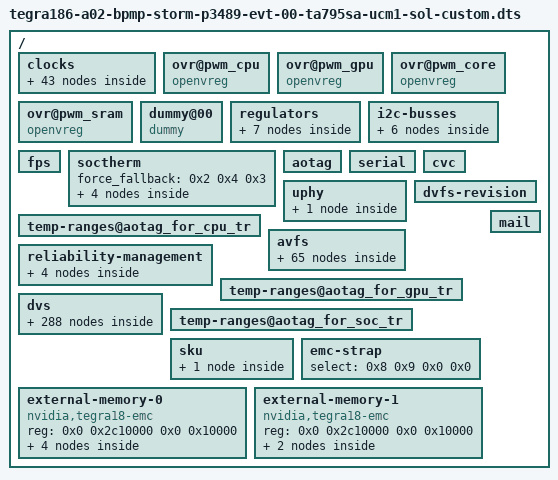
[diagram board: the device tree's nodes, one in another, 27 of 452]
/dts-v1/;

/ {
	#address-cells = <0x2>;
	#size-cells = <0x2>;

	clocks {

		init {
			i2c1 = <0x2f 0x10d 0x0 0x0>;
			i2c2 = <0xda 0x10d 0x0 0x0>;
			i2c3 = <0x4b 0x10d 0x0 0x0>;
			i2c4 = <0x56 0x10d 0x0 0x0>;
			i2c6 = <0x7d 0x10d 0x0 0x0>;
			i2c7 = <0xb6 0x10d 0x0 0x0>;
			i2c8 = <0xdb 0x10d 0x0 0x0>;
			i2c9 = <0xb7 0x10d 0x0 0x0>;
			i2c_slow = <0x5c 0x260 0x0 0x0>;
			aon_i2c_slow = <0xdd 0x260 0x0 0x0>;
			vi_i2c = <0x85 0x10d 0x0 0x0>;
			i2c12 = <0xb8 0x10d 0x0 0x0>;
			i2c13 = <0xb9 0x10d 0x0 0x0>;
			i2c14 = <0xba 0x10d 0x0 0x0>;
			xusb = <0x6f 0x10d 0x6146580 0x0>;
			xusb_core_dev = <0xf3 0x10d 0x6146580 0x0>;
			xusb_falcon = <0xf4 0x10d 0xc28cb00 0x0>;
			xusb_fs = <0xf5 0x112 0x2dc6c00 0x0>;
			xusb_core_ss = <0xf2 0x113 0x7270e00 0x0>;
			pllc4_vco = <0x20c 0x0 0x2faf0800 0x0>;
			pllc4_out0 = <0x114 0x0 0xbebc200 0x0>;
			hsic_trk = <0xf1 0x0 0x927c00 0x0>;
			pll_a1 = <0x20d 0x0 0x38be5e00 0x0>;
			aclk = <0x111 0x20d 0x11e1a300 0x0>;
			isp = <0x32 0x236 0x338eda40 0x0>;
			nvdec = <0x81 0x237 0x362e3d40 0x0>;
			nvenc = <0x83 0x238 0x350c5280 0x0>;
			nvjpg = <0x82 0x239 0x26906fc0 0x0>;
			se0 = <0x67 0x0 0x0 0x1>;
			se1 = <0x67 0x23b 0x2bde7800 0x0>;
			tsec0 = <0x51 0x0 0x0 0x20000>;
			tsec1 = <0x51 0x23c 0x1c9c3800 0x0>;
			tsecb = <0x89 0x23d 0x22274940 0x0>;
			vi = <0x33 0x23e 0x2eaba1c0 0x0>;
			vic = <0x7f 0x23f 0x2ee8aac0 0x0>;
			pll_disphub = <0x20f 0x0 0x1e53ac00 0x0>;
			nvdisplayhub = <0x9e 0x20f 0x0 0x0>;
			nafll_bpmp = <0x235 0x0 0x124f8000 0x0>;
			bpmp_apb = <0xc7 0x10d 0x0 0x0>;
			bpmp_cpu_nic = <0xc5 0x235 0x0 0x0>;
			hda = <0x66 0x10d 0x30a32c0 0x0>;
			hda2codec_2x = <0x58 0x10d 0x2dc6c00 0x0>;
			extperiph1 = <0x59 0x10d 0x0 0x0>;
			extperiph2 = <0x5a 0x10d 0x0 0x0>;
			sce_cpu_nic = <0xe4 0x23a 0x2bfcfc80 0x0>;
			sce_apb = <0xe6 0x10d 0x6146580 0x0>;
			aon_cpu = <0xd0 0x264 0x249f000 0x1>;
			aon_apb = <0xd6 0x264 0x249f000 0x1>;
			uart_fst_mipical = <0x7e 0x10d 0x40d9900 0x0>;
			aud_mclk = <0x7c 0x0 0x1770000 0x0>;
			pllnvcsi = <0x20e 0x0 0x1ad27480 0x0>;
			pll_a = <0x10f 0x0 0xf60c480 0x0>;
			axi_cbb = <0x95 0x234 0x6146580 0x0>;
			plla_out1 = <0x120 0x0 0x8f0d180 0x0>;
			ape = <0x69 0x120 0x0 0x20000>;
			host1x = <0x39 0x209 0x1d9f9e40 0x0>;
			tsec = <0x51 0x23c 0x22274940 0x0>;
			pllc2 = <0x209 0x0 0x1d9f9e40 0x0>;
			adsp = <0x111 0x20d 0x38be5e00 0x0>;
		};

		clock@bpmp_apb {
			clk-id = <0xc7>;
			allowed-parents = <0x10d 0x260 0x261>;
			mrq_hide = <0x1>;
		};

		clock@sce_apb {
			clk-id = <0xe6>;
			allowed-parents = <0x10d 0x260 0x261>;
		};

		clock@bpmp_nic {
			clk-id = <0x11f>;
			mrq_hide = <0x1>;
		};

		clock@axi_cbb {
			clk-id = <0x95>;
			allowed-parents = <0x234>;
		};

		clock@bpmp_cpu_nic {
			clk-id = <0xc5>;
			allowed-parents = <0x235>;
			mrq_hide = <0x1>;
		};

		clock@isp {
			clk-id = <0x32>;
			allowed-parents = <0x236>;
		};

		clock@nvdec {
			clk-id = <0x81>;
			allowed-parents = <0x237>;
		};

		clock@nvenc {
			clk-id = <0x83>;
			allowed-parents = <0x238>;
		};

		clock@nvjpg {
			clk-id = <0x82>;
			allowed-parents = <0x239>;
		};

		clock@sce_cpu_nic {
			clk-id = <0xe4>;
			allowed-parents = <0x23a>;
		};

		clock@se {
			clk-id = <0x67>;
			allowed-parents = <0x23b>;
		};

		clock@tsec {
			clk-id = <0x51>;
			allowed-parents = <0x23c>;
		};

		clock@tsecb {
			clk-id = <0x89>;
			allowed-parents = <0x23d>;
		};

		clock@vi {
			clk-id = <0x33>;
			allowed-parents = <0x23e>;
		};

		clock@vic {
			clk-id = <0x7f>;
			allowed-parents = <0x23f>;
		};

		clock@i2c_slow {
			clk-id = <0x5c>;
			allowed-parents = <0x260>;
		};

		clock@aon_i2c_slow {
			clk-id = <0xdd>;
			allowed-parents = <0x260>;
		};

		clock@nafll_axi_cbb {
			clk-id = <0x234>;
			mrq_hide = <0x1>;
		};

		clock@nafll_bpmp {
			clk-id = <0x235>;
			mrq_hide = <0x1>;
		};

		clock@nafll_isp {
			clk-id = <0x236>;
			mrq_hide = <0x1>;
		};

		clock@nafll_nvdec {
			clk-id = <0x237>;
			mrq_hide = <0x1>;
		};

		clock@nafll_nvenc {
			clk-id = <0x238>;
			mrq_hide = <0x1>;
		};

		clock@nafll_nvjpg {
			clk-id = <0x239>;
			mrq_hide = <0x1>;
		};

		clock@nafll_sce {
			clk-id = <0x23a>;
			mrq_hide = <0x1>;
		};

		clock@nafll_se {
			clk-id = <0x23b>;
			mrq_hide = <0x1>;
		};

		clock@nafll_tsec {
			clk-id = <0x23c>;
			mrq_hide = <0x1>;
		};

		clock@nafll_tsecb {
			clk-id = <0x23d>;
			mrq_hide = <0x1>;
		};

		clock@nafll_vi {
			clk-id = <0x23e>;
			mrq_hide = <0x1>;
		};

		clock@nafll_vic {
			clk-id = <0x23f>;
			mrq_hide = <0x1>;
		};

		clock@nafll_gpu {
			clk-id = <0x241>;
			mrq_hide = <0x1>;
		};

		clock@nafll_bcpu {
			clk-id = <0x243>;
			mrq_hide = <0x1>;
		};

		clock@nafll_mcpu {
			clk-id = <0x242>;
			mrq_hide = <0x1>;
		};

		clock@hda2codec_2x {
			clk-id = <0x58>;
			allow_fractional_divider = <0x1>;
		};

		clock@spdif_in {
			clk-id = <0x2c>;
			allow_fractional_divider = <0x1>;
		};

		clock@uarta {
			clk-id = <0x37>;
			allow_fractional_divider = <0x1>;
		};

		clock@uartb {
			clk-id = <0x38>;
			allow_fractional_divider = <0x1>;
		};

		clock@uartc {
			clk-id = <0xd7>;
			allow_fractional_divider = <0x1>;
		};

		clock@uartd {
			clk-id = <0x4d>;
			allow_fractional_divider = <0x1>;
		};

		clock@uarte {
			clk-id = <0xc2>;
			allow_fractional_divider = <0x1>;
		};

		clock@uartf {
			clk-id = <0xc3>;
			allow_fractional_divider = <0x1>;
		};

		clock@uartg {
			clk-id = <0xd8>;
			allow_fractional_divider = <0x1>;
		};

		clock@sdmmc2 {
			clk-id = <0x35>;
			allow_fractional_divider = <0x1>;
		};
	};

	ovr@pwm_cpu {
		compatible = "openvreg";
		pwm-rate = <0x5dc00>;
		pwm-off-uv = <0x927c0>;
		pwm-id = <0x7>;
		pwm-on-uv = <0x118c30>;
		enable-gpio = <0x3c>;
		linux,phandle = <0x1>;
		phandle = <0x1>;
	};

	ovr@pwm_gpu {
		compatible = "openvreg";
		pwm-rate = <0x5dc00>;
		pwm-off-uv = <0x927c0>;
		enable-gpio = <0xffff>;
		pwm-id = <0x8>;
		pwm-on-uv = <0x124f80>;
		linux,phandle = <0x3>;
		phandle = <0x3>;
	};

	ovr@pwm_core {
		compatible = "openvreg";
		pwm-rate = <0x5dc00>;
		pwm-off-uv = <0x927c0>;
		pwm-id = <0x6>;
		pwm-on-uv = <0x118c30>;
		linux,phandle = <0x5>;
		phandle = <0x5>;
	};

	ovr@pwm_sram {
		compatible = "openvreg";
		pwm-rate = <0x5dc00>;
		pwm-off-uv = <0x927c0>;
	};

	dummy@00 {
		compatible = "dummy";
		linux,phandle = <0x7>;
		phandle = <0x7>;
	};

	regulators {

		vdd_cpu {
			rail-id = <0x0 0x1>;
			dev = <0x1>;
			regulator-ramp-delay = <0xfc>;
			regulator-enable-ramp-delay = <0xa28>;
			regulator-disable-ramp-delay = <0x2ee0>;
			regulator-init-microvolt = <0xe7ef0>;
			temp-ranges = <0x2>;
			regulator-min-microvolt = <0xbbfd0 0xa6040 0xa6040 0xa6040 0xbbfd0>;
			regulator-max-microvolt = <0xef420>;
		};

		vdd_gpu {
			rail-id = <0x3>;
			dev = <0x3>;
			regulator-ramp-delay = <0xd0>;
			regulator-enable-ramp-delay = <0x7d0>;
			regulator-disable-ramp-delay = <0x2ee0>;
			regulator-init-microvolt = <0xe7ef0>;
			temp-ranges = <0x4>;
			regulator-min-microvolt = <0xbbfd0 0xa6040 0xa6040 0xa6040 0xbbfd0>;
			regulator-max-microvolt = <0xef420>;
		};

		vdd_core {
			rail-id = <0x2>;
			dev = <0x5>;
			regulator-ramp-delay = <0xd78>;
			regulator-enable-ramp-delay = <0x208>;
			regulator-disable-ramp-delay = <0x7d0>;
			regulator-init-microvolt = <0xe7ef0>;
			temp-ranges = <0x6>;
			regulator-min-microvolt = <0xaae60>;
			regulator-max-microvolt = <0x124f80>;

			bin@1717 {
				bin-bottom = <0x6b5>;
				regulator-min-microvolt = <0xe7ef0 0xb98c0 0xb98c0 0xb98c0 0xe7ef0>;
				regulator-max-microvolt = <0xef420>;
			};

			bin@1575 {
				bin-bottom = <0x627>;
				regulator-min-microvolt = <0xe7ef0 0xc3500 0xc3500 0xc3500 0xe7ef0>;
				regulator-max-microvolt = <0xef420>;
			};

			bin@1454 {
				bin-bottom = <0x5ae>;
				regulator-min-microvolt = <0xe7ef0 0xcaa30 0xcaa30 0xcaa30 0xe7ef0>;
				regulator-max-microvolt = <0xef420>;
			};
		};

		vdd_aon {
			rail-id = <0x6>;
			dev = <0x7>;
			regulator-min-microvolt = <0xc8320>;
			regulator-max-microvolt = <0xf9060>;
		};
	};

	i2c-busses {

		i2c5 {
			i2c-id = <0x5>;
			controller-clock = <0x81b3200>;
			bus-clock = <0xf4240>;
			tlow-plus-thigh = <0x8>;
			thigh = <0x2>;
			tlow = <0x4>;

			i2c_firewall_rules {

				i2c_firewall_rule@0 {
					action = <0x2>;
					addr_range_type = <0x1>;
					addr_range_low = <0x38>;
					addr_range_high = <0x3b>;
				};
			};
		};

		i2c10 {
			i2c-id = <0xa>;
			controller-clock = <0x81b3200>;
			bus-clock = <0xf4240>;
			tlow-plus-thigh = <0x8>;
			thigh = <0x2>;
			tlow = <0x4>;

			i2c_firewall_rules {

				i2c_firewall_rule@0 {
					action = <0x2>;
					addr_range_type = <0x1>;
					addr_range_low = <0x0>;
					addr_range_high = <0xff>;
				};
			};
		};
	};

	fps {
		reboot-sequence = [3c 2f 00 fc 00 3e];
		shutdown-sequence = [fc 00 3c ff 07 d0 3c 40 1a 3c 38 01 ff 0b d0 fd 00 68 3c 2f 00 3c 42 07 3c 41 c0 fc 00 3e];
		hibernate-late-sequence = [ff 17 70 3c 40 1a 3c 38 01 ff 0b d0 3c 2f 00 fc 00 3e ff 01 3c];
		resume-early-sequence = [3c 2f ce fd 00 3e ff 01 3c 3c 38 09 ff 07 d0 3c 40 1e ff 07 d0];
		sc7-sequence = [3c 1d 70 3c 1e 70 3c 1f 70 3c 20 70 3c 21 70];
		sc7-exit-sequence = [3c 1d 74 3c 1e 74 3c 1f 74 3c 20 74 3c 21 44];
	};

	soctherm {
		force_fallback = <0x2 0x4 0x3>;

		thermtrip {
			thermtrip = <0x5 0x18a88>;
		};

		throttle {
			throttle_1 = <0x2 0x184ac 0x2 0x0>;
			throttle_2 = <0x4 0x184ac 0x2 0x0>;
		};

		throttlectl {
			throttlectl_heavy = <0x1 0x7 0x7 0x64>;
		};

		edp_oc {
			oc_5 = <0x4 0x1 0x2 0x2 0x3 0x0 0xffffffff>;
		};
	};

	aotag {
		thermtrip = <0x18a88>;
		hsm_trip = <0x184ac>;
	};

	serial {
		port = <0x7>;
		has_input;
	};

	cvc {
		threshold = <0x3e8>;
		limit = <0x5>;
		jiggle;
	};

	uphy {
		lane0-owner = <0x1>;
		lane1-owner = <0x2>;
		lane2-owner = <0x1>;
		lane4-owner = <0x1>;
		lane5-owner = <0x3>;

		sata-fuse-override {
			tx-drv-amp-sel1 = <0x20>;
		};
	};

	dvfs-revision {
		mcpu = <0x2>;
		bcpu = <0x2>;
		gpu = <0x2>;
		soc-big-blocks = <0x1>;
		soc-io = <0x56>;
	};

	temp-ranges@aotag_for_cpu_tr {
		thermzone-id = <0x6>;
		tranges = <0xffffffd8 0x1e 0x19 0x32 0x2d 0x4b 0x46 0x69 0xffffffd8 0x69>;
		linux,phandle = <0x2>;
		phandle = <0x2>;
	};

	avfs {

		clock@mcpu_avfs {
			clk-id = <0x242>;
			temp-ranges = <0x2>;
			pdiv = <0x1>;
			mdiv = <0x1>;
			vfgain = <0xe 0xe 0xe 0xe 0xe 0x989680>;
			coeffs = <0xc5f71cae 0x4119cbb7 0x4640f93d 0x4025ced4 0xbb0cd89d 0xc0e99c3e 0xbfb78034 0xbb1cabb7 0xc56e31e6 0xb89a2c22>;
			vmin = <0x3f451eb8 0x0 0x0 0x3f6b5a86 0xb9187684 0x0 0x3f6b5a86 0xb9187684 0x0 0x3f6b5a86 0xb9187684 0x0 0x3f451eb8 0x0 0x0>;
			max-frequency = <0x0 0x74bad000>;
			edvd-params = <0x148060f>;
			edvd-config = <0x168>;
		};

		clock@bcpu_avfs {
			clk-id = <0x243>;
			temp-ranges = <0x2>;
			pdiv = <0x1>;
			mdiv = <0x1>;
			vfgain = <0xe 0xe 0xe 0xe 0xe 0x989680>;
			coeffs = <0xc5de9afa 0x412ca0de 0x464ad8da 0x3fa49e6e 0xbb2b6495 0xc0f8962a 0xbfde3d78 0xbb26730f 0xc56c1d32 0x39b9257a>;
			vmin = <0x3f451eb8 0x0 0x0 0x3f656d5d 0xb9212a88 0x0 0x3f656d5d 0xb9212a88 0x0 0x3f656d5d 0xb9212a88 0x0 0x3f451eb8 0x0 0x0>;
			max-frequency = <0x0 0x7270e000>;
			edvd-params = <0x148060f>;
			edvd-config = <0x168>;
		};

		clock@gpu_avfs {
			clk-id = <0x241>;
			temp-ranges = <0x4>;
			pdiv = <0x1>;
			mdiv = <0x8>;
			use-auto-skipper = <0x1>;
			vfgain = <0x2 0x2 0x2 0x2 0x2 0x989680>;
			coeffs = <0xc5f6651e 0x4157f21b 0x467f4698 0x3ee4f20b 0xbb380ca0 0xc129f43f 0xbfbf32a8 0xbb7821f9 0xc5ab0bed 0x3a204c62>;
			vmin = <0x3f451eb8 0x0 0x0 0x3f59999a 0xb8f161d8 0x0 0x3f59999a 0xb8f161d8 0x0 0x3f59999a 0xb8f161d8 0x0 0x3f451eb8 0x0 0x0>;
			max-frequency = <0x0 0x936e9d60>;

			clvc {
				use-freq-clvc = <0x1>;
				max-uvreq-offset = <0x9c40>;
				kp = <0x39d1b717>;
				min-error-threshold = <0x1820c20>;
				max-adj-step-uv = <0x2710>;
			};
		};

		clock@bpmp_avfs {
			clk-id = <0x235>;
			temp-ranges = <0x6>;
			pdiv = <0x1>;
			mdiv = <0x3>;
			use-auto-skipper = <0x1>;
			vfgain = <0x6 0x6 0x6 0x6 0x6 0x989680>;
			max-frequency = <0x0 0x314b04c0>;

			clvc {
				use-freq-clvc = <0x1>;
				max-uvreq-offset = <0x9c40>;
				kp = <0x39d1b717>;
				min-error-threshold = <0xc042c0>;
				max-adj-step-uv = <0x2710>;
				floor-uvreq = <0x1>;
			};

			bin@1717 {
				bin-bottom = <0x6b5>;
				coeffs = <0xc50e5aee 0x0 0x45b1d6b9 0x0 0x0 0x0 0x0 0x0 0xc519c49f 0x0>;
				vmin = <0x3f4f5c29 0x0 0x0 0x3f3851ec 0x0 0x0 0x3f3851ec 0x0 0x0 0x3f3851ec 0x0 0x0 0x3f4f5c29 0x0 0x0>;
			};

			bin@1575 {
				bin-bottom = <0x627>;
				coeffs = <0xc54ddeb6 0x0 0x45ee50cf 0x0 0x0 0x0 0x0 0x0 0xc553299d 0x0>;
				vmin = <0x3f4f5c29 0x0 0x0 0x3f400000 0x0 0x0 0x3f400000 0x0 0x0 0x3f400000 0x0 0x0 0x3f4f5c29 0x0 0x0>;
			};

			bin@1454 {
				bin-bottom = <0x5ae>;
				coeffs = <0xc55a9247 0x0 0x45f57b21 0x0 0x0 0x0 0x0 0x0 0xc559547c 0x0>;
				vmin = <0x3f4f5c29 0x0 0x0 0x3f47ae14 0x0 0x0 0x3f47ae14 0x0 0x0 0x3f47ae14 0x0 0x0 0x3f4f5c29 0x0 0x0>;
			};
		};

		clock@vi_avfs {
			clk-id = <0x23e>;
			temp-ranges = <0x6>;
			pdiv = <0x1>;
			mdiv = <0x3>;
			use-auto-skipper = <0x1>;
			vfgain = <0x6 0x6 0x6 0x6 0x6 0x989680>;
			max-frequency = <0x0 0x2eaba1c0>;

			clvc {
				use-freq-clvc = <0x1>;
				max-uvreq-offset = <0x9c40>;
				kp = <0x39d1b717>;
				min-error-threshold = <0xc042c0>;
				max-adj-step-uv = <0x2710>;
				floor-uvreq = <0x1>;
			};

			bin@1717 {
				bin-bottom = <0x6b5>;
				coeffs = <0xc49f137b 0x0 0x456a40fa 0x0 0x0 0x0 0x0 0x0 0xc4c4bff9 0x0>;
				vmin = <0x3f4f5c29 0x0 0x0 0x3f3851ec 0x0 0x0 0x3f3851ec 0x0 0x0 0x3f3851ec 0x0 0x0 0x3f4f5c29 0x0 0x0>;
			};

			bin@1575 {
				bin-bottom = <0x627>;
				coeffs = <0xc4c8cf1e 0x0 0x458427e9 0x0 0x0 0x0 0x0 0x0 0xc4d9c1d1 0x0>;
				vmin = <0x3f4f5c29 0x0 0x0 0x3f400000 0x0 0x0 0x3f400000 0x0 0x0 0x3f400000 0x0 0x0 0x3f4f5c29 0x0 0x0>;
			};

			bin@1454 {
				bin-bottom = <0x5ae>;
				coeffs = <0xc4be5ae1 0x0 0x4572f658 0x0 0x0 0x0 0x0 0x0 0xc4c0032c 0x0>;
				vmin = <0x3f4f5c29 0x0 0x0 0x3f47ae14 0x0 0x0 0x3f47ae14 0x0 0x0 0x3f47ae14 0x0 0x0 0x3f4f5c29 0x0 0x0>;
			};
		};

		clock@nvdec_avfs {
			clk-id = <0x237>;
			temp-ranges = <0x6>;
			pdiv = <0x1>;
			mdiv = <0x3>;
			use-auto-skipper = <0x1>;
			vfgain = <0x6 0x6 0x6 0x6 0x6 0x989680>;
			max-frequency = <0x0 0x362e3d40>;

			clvc {
				use-freq-clvc = <0x1>;
				max-uvreq-offset = <0x9c40>;
				kp = <0x39d1b717>;
				min-error-threshold = <0xc042c0>;
				max-adj-step-uv = <0x2710>;
				floor-uvreq = <0x1>;
			};

			bin@1717 {
				bin-bottom = <0x6b5>;
				coeffs = <0xc50c3fc3 0x0 0x45b86f10 0x0 0x0 0x0 0x0 0x0 0xc521911e 0x0>;
				vmin = <0x3f4f5c29 0x0 0x0 0x3f3851ec 0x0 0x0 0x3f3851ec 0x0 0x0 0x3f3851ec 0x0 0x0 0x3f4f5c29 0x0 0x0>;
			};

			bin@1575 {
				bin-bottom = <0x627>;
				coeffs = <0xc551123d 0x0 0x45f69a97 0x0 0x0 0x0 0x0 0x0 0xc55acfb7 0x0>;
				vmin = <0x3f4f5c29 0x0 0x0 0x3f400000 0x0 0x0 0x3f400000 0x0 0x0 0x3f400000 0x0 0x0 0x3f4f5c29 0x0 0x0>;
			};

			bin@1454 {
				bin-bottom = <0x5ae>;
				coeffs = <0xc531bbb0 0x0 0x45d0a009 0x0 0x0 0x0 0x0 0x0 0xc5334528 0x0>;
				vmin = <0x3f4f5c29 0x0 0x0 0x3f47ae14 0x0 0x0 0x3f47ae14 0x0 0x0 0x3f47ae14 0x0 0x0 0x3f4f5c29 0x0 0x0>;
			};
		};

		clock@nvenc_avfs {
			clk-id = <0x238>;
			temp-ranges = <0x6>;
			pdiv = <0x1>;
			mdiv = <0x3>;
			use-auto-skipper = <0x1>;
			vfgain = <0x6 0x6 0x6 0x6 0x6 0x989680>;
			max-frequency = <0x0 0x350c5280>;

			clvc {
				use-freq-clvc = <0x1>;
				max-uvreq-offset = <0x9c40>;
				kp = <0x39d1b717>;
				min-error-threshold = <0xc042c0>;
				max-adj-step-uv = <0x2710>;
				floor-uvreq = <0x1>;
			};

			bin@1717 {
				bin-bottom = <0x6b5>;
				coeffs = <0xc5035c50 0x0 0x45ab381b 0x0 0x0 0x0 0x0 0x0 0xc51226d7 0x0>;
				vmin = <0x3f4f5c29 0x0 0x0 0x3f3851ec 0x0 0x0 0x3f3851ec 0x0 0x0 0x3f3851ec 0x0 0x0 0x3f4f5c29 0x0 0x0>;
			};

			bin@1575 {
				bin-bottom = <0x627>;
				coeffs = <0xc54672cb 0x0 0x45e88d05 0x0 0x0 0x0 0x0 0x0 0xc54adf21 0x0>;
				vmin = <0x3f4f5c29 0x0 0x0 0x3f400000 0x0 0x0 0x3f400000 0x0 0x0 0x3f400000 0x0 0x0 0x3f4f5c29 0x0 0x0>;
			};

			bin@1454 {
				bin-bottom = <0x5ae>;
				coeffs = <0xc529d448 0x0 0x45c39bf5 0x0 0x0 0x0 0x0 0x0 0xc521f075 0x0>;
				vmin = <0x3f4f5c29 0x0 0x0 0x3f47ae14 0x0 0x0 0x3f47ae14 0x0 0x0 0x3f47ae14 0x0 0x0 0x3f4f5c29 0x0 0x0>;
			};
		};

		clock@nvjpg_avfs {
			clk-id = <0x239>;
			temp-ranges = <0x6>;
			pdiv = <0x2>;
			mdiv = <0x3>;
			use-auto-skipper = <0x1>;
			vfgain = <0x6 0x6 0x6 0x6 0x6 0x989680>;
			max-frequency = <0x0 0x26906fc0>;

			clvc {
				use-freq-clvc = <0x1>;
				max-uvreq-offset = <0x9c40>;
				kp = <0x39d1b717>;
				min-error-threshold = <0xc042c0>;
				max-adj-step-uv = <0x2710>;
				floor-uvreq = <0x1>;
			};

			bin@1717 {
				bin-bottom = <0x6b5>;
				coeffs = <0xc49a72f8 0x0 0x4553a62a 0x0 0x0 0x0 0x0 0x0 0xc4ad48f0 0x0>;
				vmin = <0x3f4f5c29 0x0 0x0 0x3f3851ec 0x0 0x0 0x3f3851ec 0x0 0x0 0x3f3851ec 0x0 0x0 0x3f4f5c29 0x0 0x0>;
			};

			bin@1575 {
				bin-bottom = <0x627>;
				coeffs = <0xc4c10903 0x0 0x456d0caf 0x0 0x0 0x0 0x0 0x0 0xc4bd680e 0x0>;
				vmin = <0x3f4f5c29 0x0 0x0 0x3f400000 0x0 0x0 0x3f400000 0x0 0x0 0x3f400000 0x0 0x0 0x3f4f5c29 0x0 0x0>;
			};

			bin@1454 {
				bin-bottom = <0x5ae>;
				coeffs = <0xc4dbe387 0x0 0x4582c2ea 0x0 0x0 0x0 0x0 0x0 0xc4d949d3 0x0>;
				vmin = <0x3f4f5c29 0x0 0x0 0x3f47ae14 0x0 0x0 0x3f47ae14 0x0 0x0 0x3f47ae14 0x0 0x0 0x3f4f5c29 0x0 0x0>;
			};
		};

		clock@vic_avfs {
			clk-id = <0x23f>;
			temp-ranges = <0x6>;
			pdiv = <0x2>;
			mdiv = <0x3>;
			use-auto-skipper = <0x1>;
			vfgain = <0x6 0x6 0x6 0x6 0x6 0x989680>;
			max-frequency = <0x0 0x2ee8aac0>;

			clvc {
				use-freq-clvc = <0x1>;
				max-uvreq-offset = <0x9c40>;
				kp = <0x39d1b717>;
				min-error-threshold = <0xc042c0>;
				max-adj-step-uv = <0x2710>;
				floor-uvreq = <0x1>;
			};

			bin@1717 {
				bin-bottom = <0x6b5>;
				coeffs = <0xc4cb2e03 0x0 0x4585d6d0 0x0 0x0 0x0 0x0 0x0 0xc4d6e4f2 0x0>;
				vmin = <0x3f4f5c29 0x0 0x0 0x3f3851ec 0x0 0x0 0x3f3851ec 0x0 0x0 0x3f3851ec 0x0 0x0 0x3f4f5c29 0x0 0x0>;
			};

			bin@1575 {
				bin-bottom = <0x627>;
				coeffs = <0xc54cd1c7 0x0 0x45e9ec7b 0x0 0x0 0x0 0x0 0x0 0xc54d1318 0x0>;
				vmin = <0x3f4f5c29 0x0 0x0 0x3f400000 0x0 0x0 0x3f400000 0x0 0x0 0x3f400000 0x0 0x0 0x3f4f5c29 0x0 0x0>;
			};

			bin@1454 {
				bin-bottom = <0x5ae>;
				coeffs = <0xc51f4ba7 0x0 0x45b65cc8 0x0 0x0 0x0 0x0 0x0 0xc518e283 0x0>;
				vmin = <0x3f4f5c29 0x0 0x0 0x3f47ae14 0x0 0x0 0x3f47ae14 0x0 0x0 0x3f47ae14 0x0 0x0 0x3f4f5c29 0x0 0x0>;
			};
		};

		clock@se_avfs {
			clk-id = <0x23b>;
			temp-ranges = <0x6>;
			pdiv = <0x1>;
			mdiv = <0x3>;
			use-auto-skipper = <0x1>;
			vfgain = <0x6 0x6 0x6 0x6 0x6 0x989680>;
			max-frequency = <0x0 0x2bde7800>;

			clvc {
				use-freq-clvc = <0x1>;
				max-uvreq-offset = <0x9c40>;
				kp = <0x39d1b717>;
				min-error-threshold = <0xc042c0>;
				max-adj-step-uv = <0x2710>;
				floor-uvreq = <0x1>;
			};

			bin@1717 {
				bin-bottom = <0x6b5>;
				coeffs = <0xc4cc5b99 0x0 0x4581f360 0x0 0x0 0x0 0x0 0x0 0xc4cbb9c1 0x0>;
				vmin = <0x3f4f5c29 0x0 0x0 0x3f3851ec 0x0 0x0 0x3f3851ec 0x0 0x0 0x3f3851ec 0x0 0x0 0x3f4f5c29 0x0 0x0>;
			};

			bin@1575 {
				bin-bottom = <0x627>;
				coeffs = <0xc5076c7e 0x0 0x459e2ec0 0x0 0x0 0x0 0x0 0x0 0xc4fe0523 0x0>;
				vmin = <0x3f4f5c29 0x0 0x0 0x3f400000 0x0 0x0 0x3f400000 0x0 0x0 0x3f400000 0x0 0x0 0x3f4f5c29 0x0 0x0>;
			};

			bin@1454 {
				bin-bottom = <0x5ae>;
				coeffs = <0xc4f61d98 0x0 0x458e01cf 0x0 0x0 0x0 0x0 0x0 0xc4df32a4 0x0>;
				vmin = <0x3f4f5c29 0x0 0x0 0x3f47ae14 0x0 0x0 0x3f47ae14 0x0 0x0 0x3f47ae14 0x0 0x0 0x3f4f5c29 0x0 0x0>;
			};
		};

		clock@tsec_avfs {
			clk-id = <0x23c>;
			temp-ranges = <0x6>;
			pdiv = <0x2>;
			mdiv = <0x3>;
			use-auto-skipper = <0x1>;
			vfgain = <0x6 0x6 0x6 0x6 0x6 0x989680>;
			max-frequency = <0x0 0x22274940>;

			clvc {
				use-freq-clvc = <0x1>;
				max-uvreq-offset = <0x9c40>;
				kp = <0x39d1b717>;
				min-error-threshold = <0xc042c0>;
				max-adj-step-uv = <0x2710>;
				floor-uvreq = <0x1>;
			};

			bin@1717 {
				bin-bottom = <0x6b5>;
				coeffs = <0xc4a8a1d2 0x0 0x455b5fc1 0x0 0x0 0x0 0x0 0x0 0xc4b9d455 0x0>;
				vmin = <0x3f4f5c29 0x0 0x0 0x3f3851ec 0x0 0x0 0x3f3851ec 0x0 0x0 0x3f3851ec 0x0 0x0 0x3f4f5c29 0x0 0x0>;
			};

			bin@1575 {
				bin-bottom = <0x627>;
				coeffs = <0xc4ef8f7b 0x0 0x458ef916 0x0 0x0 0x0 0x0 0x0 0xc4f87ee3 0x0>;
				vmin = <0x3f4f5c29 0x0 0x0 0x3f400000 0x0 0x0 0x3f400000 0x0 0x0 0x3f400000 0x0 0x0 0x3f4f5c29 0x0 0x0>;
			};

			bin@1454 {
				bin-bottom = <0x5ae>;
				coeffs = <0xc4ff3504 0x0 0x4593ec37 0x0 0x0 0x0 0x0 0x0 0xc502550c 0x0>;
				vmin = <0x3f4f5c29 0x0 0x0 0x3f47ae14 0x0 0x0 0x3f47ae14 0x0 0x0 0x3f47ae14 0x0 0x0 0x3f4f5c29 0x0 0x0>;
			};
		};

		clock@tsecb_avfs {
			clk-id = <0x23d>;
			temp-ranges = <0x6>;
			pdiv = <0x2>;
			mdiv = <0x3>;
			use-auto-skipper = <0x1>;
			vfgain = <0x6 0x6 0x6 0x6 0x6 0x989680>;
			max-frequency = <0x0 0x22274940>;

			clvc {
				use-freq-clvc = <0x1>;
				max-uvreq-offset = <0x9c40>;
				kp = <0x39d1b717>;
				min-error-threshold = <0xc042c0>;
				max-adj-step-uv = <0x2710>;
				floor-uvreq = <0x1>;
			};

			bin@1717 {
				bin-bottom = <0x6b5>;
				coeffs = <0xc4a8a1d2 0x0 0x455b5fc1 0x0 0x0 0x0 0x0 0x0 0xc4b9d455 0x0>;
				vmin = <0x3f4f5c29 0x0 0x0 0x3f3851ec 0x0 0x0 0x3f3851ec 0x0 0x0 0x3f3851ec 0x0 0x0 0x3f4f5c29 0x0 0x0>;
			};

			bin@1575 {
				bin-bottom = <0x627>;
				coeffs = <0xc4ef8f7b 0x0 0x458ef916 0x0 0x0 0x0 0x0 0x0 0xc4f87ee3 0x0>;
				vmin = <0x3f4f5c29 0x0 0x0 0x3f400000 0x0 0x0 0x3f400000 0x0 0x0 0x3f400000 0x0 0x0 0x3f4f5c29 0x0 0x0>;
			};

			bin@1454 {
				bin-bottom = <0x5ae>;
				coeffs = <0xc4ff3504 0x0 0x4593ec37 0x0 0x0 0x0 0x0 0x0 0xc502550c 0x0>;
				vmin = <0x3f4f5c29 0x0 0x0 0x3f47ae14 0x0 0x0 0x3f47ae14 0x0 0x0 0x3f47ae14 0x0 0x0 0x3f4f5c29 0x0 0x0>;
			};
		};

		clock@isp_avfs {
			clk-id = <0x236>;
			temp-ranges = <0x6>;
			pdiv = <0x1>;
			mdiv = <0x3>;
			use-auto-skipper = <0x1>;
			vfgain = <0x6 0x6 0x6 0x6 0x6 0x989680>;
			max-frequency = <0x0 0x338eda40>;

			clvc {
				use-freq-clvc = <0x1>;
				max-uvreq-offset = <0x9c40>;
				kp = <0x39d1b717>;
				min-error-threshold = <0xc042c0>;
				max-adj-step-uv = <0x2710>;
				floor-uvreq = <0x1>;
			};

			bin@1717 {
				bin-bottom = <0x6b5>;
				coeffs = <0xc4c63ff1 0x0 0x458bd21f 0x0 0x0 0x0 0x0 0x0 0xc4e88d02 0x0>;
				vmin = <0x3f4f5c29 0x0 0x0 0x3f3851ec 0x0 0x0 0x3f3851ec 0x0 0x0 0x3f3851ec 0x0 0x0 0x3f4f5c29 0x0 0x0>;
			};

			bin@1575 {
				bin-bottom = <0x627>;
				coeffs = <0xc4f89093 0x0 0x45a10d78 0x0 0x0 0x0 0x0 0x0 0xc5064fd2 0x0>;
				vmin = <0x3f4f5c29 0x0 0x0 0x3f400000 0x0 0x0 0x3f400000 0x0 0x0 0x3f400000 0x0 0x0 0x3f4f5c29 0x0 0x0>;
			};

			bin@1454 {
				bin-bottom = <0x5ae>;
				coeffs = <0xc4ebcc9b 0x0 0x459270be 0x0 0x0 0x0 0x0 0x0 0xc4eb6bcd 0x0>;
				vmin = <0x3f4f5c29 0x0 0x0 0x3f47ae14 0x0 0x0 0x3f47ae14 0x0 0x0 0x3f47ae14 0x0 0x0 0x3f4f5c29 0x0 0x0>;
			};
		};

		clock@axi_cbb_avfs {
			clk-id = <0x234>;
			temp-ranges = <0x6>;
			pdiv = <0x2>;
			mdiv = <0x1>;
			use-auto-skipper = <0x1>;
			vfgain = <0x6 0x6 0x6 0x6 0x6 0x989680>;
			max-frequency = <0x0 0x1e753dc0>;

			clvc {
				use-freq-clvc = <0x1>;
				max-uvreq-offset = <0x9c40>;
				kp = <0x39d1b717>;
				min-error-threshold = <0xc042c0>;
				max-adj-step-uv = <0x2710>;
				floor-uvreq = <0x1>;
			};

			bin@1717 {
				bin-bottom = <0x6b5>;
				coeffs = <0xc44cfaf0 0x0 0x451a3a8d 0x0 0x0 0x0 0x0 0x0 0xc48b0ad2 0x0>;
				vmin = <0x3f4f5c29 0x0 0x0 0x3f3851ec 0x0 0x0 0x3f3851ec 0x0 0x0 0x3f3851ec 0x0 0x0 0x3f4f5c29 0x0 0x0>;
			};

			bin@1575 {
				bin-bottom = <0x627>;
				coeffs = <0xc49ba108 0x0 0x454cb907 0x0 0x0 0x0 0x0 0x0 0xc4bbc3f6 0x0>;
				vmin = <0x3f4f5c29 0x0 0x0 0x3f400000 0x0 0x0 0x3f400000 0x0 0x0 0x3f400000 0x0 0x0 0x3f4f5c29 0x0 0x0>;
			};

			bin@1454 {
				bin-bottom = <0x5ae>;
				coeffs = <0xc4f04066 0x0 0x458e842c 0x0 0x0 0x0 0x0 0x0 0xc5037e38 0x0>;
				vmin = <0x3f4f5c29 0x0 0x0 0x3f47ae14 0x0 0x0 0x3f47ae14 0x0 0x0 0x3f47ae14 0x0 0x0 0x3f4f5c29 0x0 0x0>;
			};
		};

		clock@sce_avfs {
			clk-id = <0x23a>;
			temp-ranges = <0x6>;
			pdiv = <0x1>;
			mdiv = <0x3>;
			use-auto-skipper = <0x1>;
			vfgain = <0x6 0x6 0x6 0x6 0x6 0x989680>;
			max-frequency = <0x0 0x2bfcfc80>;

			clvc {
				use-freq-clvc = <0x1>;
				max-uvreq-offset = <0x9c40>;
				kp = <0x39d1b717>;
				min-error-threshold = <0xc042c0>;
				max-adj-step-uv = <0x2710>;
				floor-uvreq = <0x1>;
			};

			bin@1717 {
				bin-bottom = <0x6b5>;
				coeffs = <0xc4402b04 0x0 0x451f536e 0x0 0x0 0x0 0x0 0x0 0xc46f86e1 0x0>;
				vmin = <0x3f4f5c29 0x0 0x0 0x3f3851ec 0x0 0x0 0x3f3851ec 0x0 0x0 0x3f3851ec 0x0 0x0 0x3f4f5c29 0x0 0x0>;
			};

			bin@1575 {
				bin-bottom = <0x627>;
				coeffs = <0xc49bd3b0 0x0 0x4557a990 0x0 0x0 0x0 0x0 0x0 0xc4aec863 0x0>;
				vmin = <0x3f4f5c29 0x0 0x0 0x3f400000 0x0 0x0 0x3f400000 0x0 0x0 0x3f400000 0x0 0x0 0x3f4f5c29 0x0 0x0>;
			};

			bin@1454 {
				bin-bottom = <0x5ae>;
				coeffs = <0xc4d23545 0x0 0x4583ecc4 0x0 0x0 0x0 0x0 0x0 0xc4dc535f 0x0>;
				vmin = <0x3f4f5c29 0x0 0x0 0x3f47ae14 0x0 0x0 0x3f47ae14 0x0 0x0 0x3f47ae14 0x0 0x0 0x3f4f5c29 0x0 0x0>;
			};
		};

		clock@disp_avfs {
			clk-id = <0x240>;
			temp-ranges = <0x6>;
			pdiv = <0x2>;
			mdiv = <0x1>;
			use-auto-skipper = <0x1>;
			vfgain = <0x6 0x6 0x6 0x6 0x6 0x989680>;
			coeffs = <0xc3ebbef5 0x0 0x449fa601 0x0 0x0 0x0 0x0 0x0 0xc3afb6aa 0x0>;
			vmin = <0x3f4f5c29 0x0 0x0 0x3f47ae14 0x0 0x0 0x3f47ae14 0x0 0x0 0x3f47ae14 0x0 0x0 0x3f4f5c29 0x0 0x0>;
		};
	};

	reliability-management {

		vdd_mcpu {
			rail-id = <0x0>;
			thermzone-id = <0x5>;
			voltage-caps = <0xffffffd8 0x46 0xecd10 0x41 0x5a 0xecd10 0x55 0xc8 0xe6b68>;
		};

		vdd_bcpu {
			rail-id = <0x1>;
			thermzone-id = <0x5>;
			voltage-caps = <0xffffffd8 0x46 0xef420 0x41 0x5a 0xef420 0x55 0xc8 0xe6b68>;
		};

		vdd_gpu {
			rail-id = <0x3>;
			thermzone-id = <0x6>;
			voltage-caps = <0xffffffd8 0x46 0xef420 0x41 0x5a 0xef420 0x55 0xc8 0xe6b68>;
		};

		vdd_core {
			rail-id = <0x2>;
			thermzone-id = <0x6>;
			voltage-caps = <0xffffffd8 0x46 0xef420 0x41 0x50 0xef420 0x4b 0xc8 0xe6b68>;
		};
	};

	temp-ranges@aotag_for_gpu_tr {
		thermzone-id = <0x6>;
		tranges = <0xffffffd8 0x1e 0x19 0x32 0x2d 0x4b 0x46 0x69 0xffffffd8 0x69>;
		linux,phandle = <0x4>;
		phandle = <0x4>;
	};

	dvs {

		clock@gpu {
			clk-id = <0x1>;

			rail@vdd_gpu {
				rail-id = <0x3>;
				temp-ranges = <0x4>;
				rail-passive = <0x1>;

				opp@0 {
					cvb-coeffs = <0x3f451eb8 0x0 0x0 0x3f59999a 0xb8f161d8 0x0 0x3f59999a 0xb8f161d8 0x0 0x3f59999a 0xb8f161d8 0x0 0x3f451eb8 0x0 0x0>;
					freq = <0x0 0x18519600>;
				};
			};
		};

		clock@emc {
			clk-id = <0x3a>;

			rail@vdd_core {
				rail-id = <0x2>;

				opp@0 {
					cvb-coeffs = <0x3f547ae1 0x0 0x0>;
					freq = <0x0 0x5f5e1000>;
				};

				opp@1 {
					cvb-coeffs = <0x3f4ccccd 0x0 0x0>;
					freq = <0x0 0x5f5e1000>;
				};

				opp@2 {
					cvb-coeffs = <0x3f428f5c 0x0 0x0>;
					freq = <0x0 0x5f5e1000>;
				};
			};
		};

		clock@host1x {
			clk-id = <0x39>;

			rail@vdd_core {
				rail-id = <0x2>;

				bin@1717 {
					bin-bottom = <0x6b5>;
					coeffs = <0xc429286e 0x45044c6f 0xc4563a65>;
					max-frequency = <0x0 0x1d9f9e40>;
				};

				bin@1575 {
					bin-bottom = <0x627>;
					coeffs = <0xc4609efc 0x45164e1f 0xc46c7892>;
					max-frequency = <0x0 0x1d9f9e40>;
				};

				bin@1454 {
					bin-bottom = <0x5ae>;
					coeffs = <0xc49e3871 0x4541ead5 0xc4a402e5>;
					max-frequency = <0x0 0x1d9f9e40>;
				};
			};
		};

		clock@adsp {
			clk-id = <0x111>;

			rail@vdd_core {
				rail-id = <0x2>;

				bin@1717 {
					bin-bottom = <0x6b5>;
					coeffs = <0xc59b2ff4 0x462ef009 0xc59d6011>;
					max-frequency = <0x0 0x38be5e00>;
				};

				bin@1575 {
					bin-bottom = <0x627>;
					coeffs = <0xc5a5e785 0x46332ed8 0xc59c70fd>;
					max-frequency = <0x0 0x38be5e00>;
				};

				bin@1454 {
					bin-bottom = <0x5ae>;
					coeffs = <0xc58f2da0 0x46155b8f 0xc57599a0>;
					max-frequency = <0x0 0x38be5e00>;
				};
			};
		};

		clock@ape {
			clk-id = <0x69>;

			rail@vdd_core {
				rail-id = <0x2>;

				bin@1717 {
					bin-bottom = <0x6b5>;
					coeffs = <0xc55c1418 0x45f02df3 0xc5522e11>;
					max-frequency = <0x0 0x217f7080>;
				};

				bin@1575 {
					bin-bottom = <0x627>;
					coeffs = <0xc4cfaf6a 0x4548591c 0xc452c5ee>;
					max-frequency = <0x0 0x217f7080>;
				};

				bin@1454 {
					bin-bottom = <0x5ae>;
					coeffs = <0xc5091dbc 0x458c2fc7 0xc4d089ec>;
					max-frequency = <0x0 0x217f7080>;
				};
			};
		};

		

		clock@bpmp_apb {
			clk-id = <0xc7>;

			rail@vdd_core {
				rail-id = <0x2>;

				bin@1717 {
					bin-bottom = <0x6b5>;
					coeffs = <0x43cc0000 0x0 0x0>;
					max-frequency = <0x0 0x18519600>;
				};

				bin@1575 {
					bin-bottom = <0x627>;
					coeffs = <0x43cc0000 0x0 0x0>;
					max-frequency = <0x0 0x18519600>;
				};

				bin@1454 {
					bin-bottom = <0x5ae>;
					coeffs = <0x43cc0000 0x0 0x0>;
					max-frequency = <0x0 0x18519600>;
				};
			};
		};

		clock@sce_apb {
			clk-id = <0xe6>;

			rail@vdd_core {
				rail-id = <0x2>;

				bin@1717 {
					bin-bottom = <0x6b5>;
					coeffs = <0x42cc0000 0x0 0x0>;
					max-frequency = <0x0 0x6146580>;
				};

				bin@1575 {
					bin-bottom = <0x627>;
					coeffs = <0x42cc0000 0x0 0x0>;
					max-frequency = <0x0 0x6146580>;
				};

				bin@1454 {
					bin-bottom = <0x5ae>;
					coeffs = <0x42cc0000 0x0 0x0>;
					max-frequency = <0x0 0x6146580>;
				};
			};
		};

		clock@nvcsi {
			clk-id = <0xb4>;

			rail@vdd_core {
				rail-id = <0x2>;

				opp@0 {
					cvb-coeffs = <0x3f51eb85 0x0 0x0>;
					freq = <0x0 0xd693a40>;
				};
			};
		};

		clock@nvcsilp {
			clk-id = <0xb5>;

			rail@vdd_core {
				rail-id = <0x2>;

				opp@0 {
					cvb-coeffs = <0x3f51eb85 0x0 0x0>;
					freq = <0x0 0xc28cb00>;
				};
			};
		};

		clock@uart_fst_mipical {
			clk-id = <0x7e>;

			rail@vdd_core {
				rail-id = <0x2>;

				opp@0 {
					cvb-coeffs = <0x3f51eb85 0x0 0x0>;
					freq = <0x0 0x40d9900>;
				};
			};
		};

		clock@dsia {
			clk-id = <0x73>;

			rail@vdd_core {
				rail-id = <0x2>;

				opp@0 {
					cvb-coeffs = <0x3f51eb85 0x0 0x0>;
					freq = <0x0 0x5b136e00>;
				};
			};
		};

		clock@dsib {
			clk-id = <0x76>;

			rail@vdd_core {
				rail-id = <0x2>;

				opp@0 {
					cvb-coeffs = <0x3f51eb85 0x0 0x0>;
					freq = <0x0 0x5b136e00>;
				};
			};
		};

		clock@dsic {
			clk-id = <0xe7>;

			rail@vdd_core {
				rail-id = <0x2>;

				opp@0 {
					cvb-coeffs = <0x3f51eb85 0x0 0x0>;
					freq = <0x0 0x5b136e00>;
				};
			};
		};

		clock@dsid {
			clk-id = <0xe9>;

			rail@vdd_core {
				rail-id = <0x2>;

				opp@0 {
					cvb-coeffs = <0x3f51eb85 0x0 0x0>;
					freq = <0x0 0x5b136e00>;
				};
			};
		};

		clock@dsia_lp {
			clk-id = <0x75>;

			rail@vdd_core {
				rail-id = <0x2>;

				opp@0 {
					cvb-coeffs = <0x3f51eb85 0x0 0x0>;
					freq = <0x0 0x6146580>;
				};
			};
		};

		clock@dsib_lp {
			clk-id = <0x77>;

			rail@vdd_core {
				rail-id = <0x2>;

				opp@0 {
					cvb-coeffs = <0x3f51eb85 0x0 0x0>;
					freq = <0x0 0x6146580>;
				};
			};
		};

		clock@dsic_lp {
			clk-id = <0xe8>;

			rail@vdd_core {
				rail-id = <0x2>;

				opp@0 {
					cvb-coeffs = <0x3f51eb85 0x0 0x0>;
					freq = <0x0 0x6146580>;
				};
			};
		};

		clock@dsid_lp {
			clk-id = <0xea>;

			rail@vdd_core {
				rail-id = <0x2>;

				opp@0 {
					cvb-coeffs = <0x3f51eb85 0x0 0x0>;
					freq = <0x0 0x6146580>;
				};
			};
		};

		clock@sor0 {
			clk-id = <0x61>;

			rail@vdd_core {
				rail-id = <0x2>;

				opp@0 {
					cvb-coeffs = <0x3f51eb85 0x0 0x0>;
					freq = <0x0 0x2367b880>;
				};
			};
		};

		clock@sor1 {
			clk-id = <0x5d>;

			rail@vdd_core {
				rail-id = <0x2>;

				opp@0 {
					cvb-coeffs = <0x3f51eb85 0x0 0x0>;
					freq = <0x0 0x2367b880>;
				};
			};
		};

		clock@i2s1 {
			clk-id = <0x4f>;

			rail@vdd_core {
				rail-id = <0x2>;

				opp@0 {
					cvb-coeffs = <0x3f51eb85 0x0 0x0>;
					freq = <0x0 0x17703e8>;
				};
			};
		};

		clock@i2s2 {
			clk-id = <0x2a>;

			rail@vdd_core {
				rail-id = <0x2>;

				opp@0 {
					cvb-coeffs = <0x3f51eb85 0x0 0x0>;
					freq = <0x0 0x17703e8>;
				};
			};
		};

		clock@i2s3 {
			clk-id = <0x2b>;

			rail@vdd_core {
				rail-id = <0x2>;

				opp@0 {
					cvb-coeffs = <0x3f51eb85 0x0 0x0>;
					freq = <0x0 0x17703e8>;
				};
			};
		};

		clock@i2s4 {
			clk-id = <0x54>;

			rail@vdd_core {
				rail-id = <0x2>;

				opp@0 {
					cvb-coeffs = <0x3f51eb85 0x0 0x0>;
					freq = <0x0 0x17703e8>;
				};
			};
		};

		clock@i2s5 {
			clk-id = <0x55>;

			rail@vdd_core {
				rail-id = <0x2>;

				opp@0 {
					cvb-coeffs = <0x3f51eb85 0x0 0x0>;
					freq = <0x0 0x17703e8>;
				};
			};
		};

		clock@i2s6 {
			clk-id = <0x9a>;

			rail@vdd_core {
				rail-id = <0x2>;

				opp@0 {
					cvb-coeffs = <0x3f51eb85 0x0 0x0>;
					freq = <0x0 0x17703e8>;
				};
			};
		};

		clock@spdif_in {
			clk-id = <0x2c>;

			rail@vdd_core {
				rail-id = <0x2>;

				opp@0 {
					cvb-coeffs = <0x3f51eb85 0x0 0x0>;
					freq = <0x0 0x9ba3c00>;
				};
			};
		};

		clock@dmic1 {
			clk-id = <0x7a>;

			rail@vdd_core {
				rail-id = <0x2>;

				opp@0 {
					cvb-coeffs = <0x3f51eb85 0x0 0x0>;
					freq = <0x0 0xbb83e8>;
				};
			};
		};

		clock@dmic2 {
			clk-id = <0x7b>;

			rail@vdd_core {
				rail-id = <0x2>;

				opp@0 {
					cvb-coeffs = <0x3f51eb85 0x0 0x0>;
					freq = <0x0 0xbb83e8>;
				};
			};
		};

		clock@dmic3 {
			clk-id = <0x96>;

			rail@vdd_core {
				rail-id = <0x2>;

				opp@0 {
					cvb-coeffs = <0x3f51eb85 0x0 0x0>;
					freq = <0x0 0xbb83e8>;
				};
			};
		};

		clock@dmic4 {
			clk-id = <0x97>;

			rail@vdd_core {
				rail-id = <0x2>;

				opp@0 {
					cvb-coeffs = <0x3f51eb85 0x0 0x0>;
					freq = <0x0 0xbb83e8>;
				};
			};
		};

		clock@dmic5 {
			clk-id = <0xdf>;

			rail@vdd_aon {
				rail-id = <0x6>;

				opp@0 {
					cvb-coeffs = <0x3f51eb85 0x0 0x0>;
					freq = <0x0 0xbb83e8>;
				};
			};
		};

		clock@hda {
			clk-id = <0x66>;

			rail@vdd_core {
				rail-id = <0x2>;

				opp@0 {
					cvb-coeffs = <0x3f51eb85 0x0 0x0>;
					freq = <0x0 0x30a32c0>;
				};
			};
		};

		clock@hda2codec_2x {
			clk-id = <0x58>;

			rail@vdd_core {
				rail-id = <0x2>;

				opp@0 {
					cvb-coeffs = <0x3f51eb85 0x0 0x0>;
					freq = <0x0 0x2dc6c00>;
				};
			};
		};

		clock@dspk1 {
			clk-id = <0x98>;

			rail@vdd_core {
				rail-id = <0x2>;

				opp@0 {
					cvb-coeffs = <0x3f51eb85 0x0 0x0>;
					freq = <0x0 0x30d4000>;
				};
			};
		};

		clock@dspk2 {
			clk-id = <0x99>;

			rail@vdd_core {
				rail-id = <0x2>;

				opp@0 {
					cvb-coeffs = <0x3f51eb85 0x0 0x0>;
					freq = <0x0 0x30d4000>;
				};
			};
		};

		clock@maud {
			clk-id = <0x88>;

			rail@vdd_core {
				rail-id = <0x2>;

				opp@0 {
					cvb-coeffs = <0x3f51eb85 0x0 0x0>;
					freq = <0x0 0x6146580>;
				};
			};
		};

		clock@sdmmc1 {
			clk-id = <0x34>;

			rail@vdd_core {
				rail-id = <0x2>;

				opp@0 {
					cvb-coeffs = <0x3f51eb85 0x0 0x0>;
					freq = <0x0 0xc28cb00>;
				};
			};
		};

		clock@sdmmc2 {
			clk-id = <0x35>;

			rail@vdd_core {
				rail-id = <0x2>;

				opp@0 {
					cvb-coeffs = <0x3f51eb85 0x0 0x0>;
					freq = <0x0 0x9ba3c00>;
				};
			};
		};

		clock@sdmmc3 {
			clk-id = <0x4c>;

			rail@vdd_core {
				rail-id = <0x2>;

				opp@0 {
					cvb-coeffs = <0x3f51eb85 0x0 0x0>;
					freq = <0x0 0xc28cb00>;
				};
			};
		};

		clock@sdmmc4 {
			clk-id = <0x36>;

			rail@vdd_core {
				rail-id = <0x2>;

				opp@0 {
					cvb-coeffs = <0x3f51eb85 0x0 0x0>;
					freq = <0x0 0xfea18c0>;
				};
			};
		};

		clock@sdmmc_legacy_tm {
			clk-id = <0x80>;

			rail@vdd_core {
				rail-id = <0x2>;

				opp@0 {
					cvb-coeffs = <0x3f51eb85 0x0 0x0>;
					freq = <0x0 0xb71b00>;
				};
			};
		};

		clock@xusb_host {
			clk-id = <0x6f>;

			rail@vdd_core {
				rail-id = <0x2>;

				opp@0 {
					cvb-coeffs = <0x3f51eb85 0x0 0x0>;
					freq = <0x0 0x81b3200>;
				};
			};
		};

		clock@xusb_falcon {
			clk-id = <0xf4>;

			rail@vdd_core {
				rail-id = <0x2>;

				opp@0 {
					cvb-coeffs = <0x3f51eb85 0x0 0x0>;
					freq = <0x0 0xc28cb00>;
				};
			};
		};

		clock@xusb_fs {
			clk-id = <0xf5>;

			rail@vdd_core {
				rail-id = <0x2>;

				opp@0 {
					cvb-coeffs = <0x3f51eb85 0x0 0x0>;
					freq = <0x0 0x2dc6c00>;
				};
			};
		};

		clock@xusb_core_dev {
			clk-id = <0xf3>;

			rail@vdd_core {
				rail-id = <0x2>;

				opp@0 {
					cvb-coeffs = <0x3f51eb85 0x0 0x0>;
					freq = <0x0 0x81b3200>;
				};
			};
		};

		clock@xusb_ss {
			clk-id = <0xf2>;

			rail@vdd_core {
				rail-id = <0x2>;

				opp@0 {
					cvb-coeffs = <0x3f51eb85 0x0 0x0>;
					freq = <0x0 0x7270e00>;
				};
			};
		};

		clock@sata {
			clk-id = <0x63>;

			rail@vdd_core {
				rail-id = <0x2>;

				opp@0 {
					cvb-coeffs = <0x3f51eb85 0x0 0x0>;
					freq = <0x0 0x6146580>;
				};
			};
		};

		clock@sata_oob {
			clk-id = <0x64>;

			rail@vdd_core {
				rail-id = <0x2>;

				opp@0 {
					cvb-coeffs = <0x3f51eb85 0x0 0x0>;
					freq = <0x0 0xc28cb00>;
				};
			};
		};

		clock@ipfs {
			clk-id = <0x4>;

			rail@vdd_core {
				rail-id = <0x2>;

				opp@0 {
					cvb-coeffs = <0x3f51eb85 0x0 0x0>;
					freq = <0x0 0x18519600>;
				};
			};
		};

		clock@pex_sata_usb_rx_byp {
			clk-id = <0xec>;

			rail@vdd_core {
				rail-id = <0x2>;

				opp@0 {
					cvb-coeffs = <0x3f51eb85 0x0 0x0>;
					freq = <0x0 0xc28cb00>;
				};
			};
		};

		clock@pll0_mgmt {
			clk-id = <0x12e>;

			rail@vdd_core {
				rail-id = <0x2>;

				opp@0 {
					cvb-coeffs = <0x3f51eb85 0x0 0x0>;
					freq = <0x0 0x6146580>;
				};
			};
		};

		clock@pll1_mgmt {
			clk-id = <0x12f>;

			rail@vdd_core {
				rail-id = <0x2>;

				opp@0 {
					cvb-coeffs = <0x3f51eb85 0x0 0x0>;
					freq = <0x0 0x6146580>;
				};
			};
		};

		clock@core_pll_fixed {
			clk-id = <0x94>;

			rail@vdd_core {
				rail-id = <0x2>;

				opp@0 {
					cvb-coeffs = <0x3f51eb85 0x0 0x0>;
					freq = <0x0 0xc6d7520>;
				};
			};
		};

		clock@i2c1 {
			clk-id = <0x2f>;

			rail@vdd_core {
				rail-id = <0x2>;

				opp@0 {
					cvb-coeffs = <0x3f51eb85 0x0 0x0>;
					freq = <0x0 0x18519600>;
				};
			};
		};

		clock@i2c2 {
			clk-id = <0xda>;

			rail@vdd_aon {
				rail-id = <0x6>;

				opp@0 {
					cvb-coeffs = <0x3f51eb85 0x0 0x0>;
					freq = <0x0 0x18519600>;
				};
			};
		};

		clock@i2c3 {
			clk-id = <0x4b>;

			rail@vdd_core {
				rail-id = <0x2>;

				opp@0 {
					cvb-coeffs = <0x3f51eb85 0x0 0x0>;
					freq = <0x0 0x18519600>;
				};
			};
		};

		clock@i2c4 {
			clk-id = <0x56>;

			rail@vdd_core {
				rail-id = <0x2>;

				opp@0 {
					cvb-coeffs = <0x3f51eb85 0x0 0x0>;
					freq = <0x0 0x18519600>;
				};
			};
		};

		clock@i2c6 {
			clk-id = <0x7d>;

			rail@vdd_core {
				rail-id = <0x2>;

				opp@0 {
					cvb-coeffs = <0x3f51eb85 0x0 0x0>;
					freq = <0x0 0x18519600>;
				};
			};
		};

		clock@i2c7 {
			clk-id = <0xb6>;

			rail@vdd_core {
				rail-id = <0x2>;

				opp@0 {
					cvb-coeffs = <0x3f51eb85 0x0 0x0>;
					freq = <0x0 0x18519600>;
				};
			};
		};

		clock@i2c8 {
			clk-id = <0xdb>;

			rail@vdd_aon {
				rail-id = <0x6>;

				opp@0 {
					cvb-coeffs = <0x3f51eb85 0x0 0x0>;
					freq = <0x0 0x18519600>;
				};
			};
		};

		clock@i2c9 {
			clk-id = <0xb7>;

			rail@vdd_core {
				rail-id = <0x2>;

				opp@0 {
					cvb-coeffs = <0x3f51eb85 0x0 0x0>;
					freq = <0x0 0x18519600>;
				};
			};
		};

		clock@i2c10 {
			clk-id = <0xdc>;

			rail@vdd_core {
				rail-id = <0x2>;

				opp@0 {
					cvb-coeffs = <0x3f51eb85 0x0 0x0>;
					freq = <0x0 0x18519600>;
				};
			};
		};

		clock@i2c_slow {
			clk-id = <0x5c>;

			rail@vdd_core {
				rail-id = <0x2>;

				opp@0 {
					cvb-coeffs = <0x3f51eb85 0x0 0x0>;
					freq = <0x0 0x8000>;
				};
			};
		};

		clock@aon_i2c_slow {
			clk-id = <0xdd>;

			rail@vdd_aon {
				rail-id = <0x6>;

				opp@0 {
					cvb-coeffs = <0x3f51eb85 0x0 0x0>;
					freq = <0x0 0x8000>;
				};
			};
		};

		clock@pwm1 {
			clk-id = <0xbb>;

			rail@vdd_core {
				rail-id = <0x2>;

				opp@0 {
					cvb-coeffs = <0x3f51eb85 0x0 0x0>;
					freq = <0x0 0x6146580>;
				};
			};
		};

		clock@pwm2 {
			clk-id = <0xbc>;

			rail@vdd_core {
				rail-id = <0x2>;

				opp@0 {
					cvb-coeffs = <0x3f51eb85 0x0 0x0>;
					freq = <0x0 0x6146580>;
				};
			};
		};

		clock@pwm3 {
			clk-id = <0xbd>;

			rail@vdd_core {
				rail-id = <0x2>;

				opp@0 {
					cvb-coeffs = <0x3f51eb85 0x0 0x0>;
					freq = <0x0 0x6146580>;
				};
			};
		};

		clock@pwm4 {
			clk-id = <0xe1>;

			rail@vdd_aon {
				rail-id = <0x6>;

				opp@0 {
					cvb-coeffs = <0x3f51eb85 0x0 0x0>;
					freq = <0x0 0x249f000>;
				};
			};
		};

		clock@pwm5 {
			clk-id = <0xbe>;

			rail@vdd_core {
				rail-id = <0x2>;

				opp@0 {
					cvb-coeffs = <0x3f51eb85 0x0 0x0>;
					freq = <0x0 0x6146580>;
				};
			};
		};

		clock@pwm6 {
			clk-id = <0xbf>;

			rail@vdd_core {
				rail-id = <0x2>;

				opp@0 {
					cvb-coeffs = <0x3f51eb85 0x0 0x0>;
					freq = <0x0 0x6146580>;
				};
			};
		};

		clock@pwm7 {
			clk-id = <0xc0>;

			rail@vdd_core {
				rail-id = <0x2>;

				opp@0 {
					cvb-coeffs = <0x3f51eb85 0x0 0x0>;
					freq = <0x0 0x6146580>;
				};
			};
		};

		clock@pwm8 {
			clk-id = <0xc1>;

			rail@vdd_core {
				rail-id = <0x2>;

				opp@0 {
					cvb-coeffs = <0x3f51eb85 0x0 0x0>;
					freq = <0x0 0x6146580>;
				};
			};
		};

		clock@tach {
			clk-id = <0xa6>;

			rail@vdd_core {
				rail-id = <0x2>;

				opp@0 {
					cvb-coeffs = <0x3f51eb85 0x0 0x0>;
					freq = <0x0 0x124f800>;
				};
			};
		};

		clock@spi1 {
			clk-id = <0x31>;

			rail@vdd_core {
				rail-id = <0x2>;

				opp@0 {
					cvb-coeffs = <0x3f51eb85 0x0 0x0>;
					freq = <0x0 0x40d9900>;
				};
			};
		};

		clock@spi2 {
			clk-id = <0xde>;

			rail@vdd_aon {
				rail-id = <0x6>;

				opp@0 {
					cvb-coeffs = <0x3f51eb85 0x0 0x0>;
					freq = <0x0 0x40d9900>;
				};
			};
		};

		clock@spi3 {
			clk-id = <0x2e>;

			rail@vdd_core {
				rail-id = <0x2>;

				opp@0 {
					cvb-coeffs = <0x3f51eb85 0x0 0x0>;
					freq = <0x0 0x40d9900>;
				};
			};
		};

		clock@spi4 {
			clk-id = <0x4a>;

			rail@vdd_core {
				rail-id = <0x2>;

				opp@0 {
					cvb-coeffs = <0x3f51eb85 0x0 0x0>;
					freq = <0x0 0x40d9900>;
				};
			};
		};

		clock@can1 {
			clk-id = <0xd2>;

			rail@vdd_aon {
				rail-id = <0x6>;

				opp@0 {
					cvb-coeffs = <0x3f51eb85 0x0 0x0>;
					freq = <0x0 0x2625a00>;
				};
			};
		};

		clock@can2 {
			clk-id = <0xd4>;

			rail@vdd_aon {
				rail-id = <0x6>;

				opp@0 {
					cvb-coeffs = <0x3f51eb85 0x0 0x0>;
					freq = <0x0 0x2625a00>;
				};
			};
		};

		clock@eqos_tx {
			clk-id = <0xf0>;

			rail@vdd_core {
				rail-id = <0x2>;

				opp@0 {
					cvb-coeffs = <0x3f51eb85 0x0 0x0>;
					freq = <0x0 0x7735940>;
				};
			};
		};

		clock@eqos_axi {
			clk-id = <0xa7>;

			rail@vdd_core {
				rail-id = <0x2>;

				opp@0 {
					cvb-coeffs = <0x3f51eb85 0x0 0x0>;
					freq = <0x0 0x7735940>;
				};
			};
		};

		clock@eqos_ptp_ref {
			clk-id = <0xef>;

			rail@vdd_core {
				rail-id = <0x2>;

				opp@0 {
					cvb-coeffs = <0x3f51eb85 0x0 0x0>;
					freq = <0x0 0x7735940>;
				};
			};
		};

		clock@tsc {
			clk-id = <0xe2>;

			rail@vdd_core {
				rail-id = <0x2>;

				opp@0 {
					cvb-coeffs = <0x3f51eb85 0x0 0x0>;
					freq = <0x0 0x249f000>;
				};
			};
		};

		clock@aon_touch {
			clk-id = <0xe0>;

			rail@vdd_aon {
				rail-id = <0x6>;

				opp@0 {
					cvb-coeffs = <0x3f51eb85 0x0 0x0>;
					freq = <0x0 0x26e8f00>;
				};
			};
		};

		clock@extperiph1 {
			clk-id = <0x59>;

			rail@vdd_core {
				rail-id = <0x2>;

				opp@0 {
					cvb-coeffs = <0x3f51eb85 0x0 0x0>;
					freq = <0x0 0x23619e0>;
				};
			};
		};

		clock@extperiph2 {
			clk-id = <0x5a>;

			rail@vdd_core {
				rail-id = <0x2>;

				opp@0 {
					cvb-coeffs = <0x3f51eb85 0x0 0x0>;
					freq = <0x0 0x23619e0>;
				};
			};
		};

		clock@extperiph3 {
			clk-id = <0x5b>;

			rail@vdd_core {
				rail-id = <0x2>;

				opp@0 {
					cvb-coeffs = <0x3f51eb85 0x0 0x0>;
					freq = <0x0 0x23619e0>;
				};
			};
		};

		clock@extperiph4 {
			clk-id = <0x49>;

			rail@vdd_core {
				rail-id = <0x2>;

				opp@0 {
					cvb-coeffs = <0x3f51eb85 0x0 0x0>;
					freq = <0x0 0x23619e0>;
				};
			};
		};

		clock@aud_mclk {
			clk-id = <0x7c>;

			rail@vdd_core {
				rail-id = <0x2>;

				opp@0 {
					cvb-coeffs = <0x3f51eb85 0x0 0x0>;
					freq = <0x0 0x2ee0000>;
				};
			};
		};

		clock@qspi {
			clk-id = <0x84>;

			rail@vdd_core {
				rail-id = <0x2>;

				opp@0 {
					cvb-coeffs = <0x3f51eb85 0x0 0x0>;
					freq = <0x0 0xc28cb00>;
				};
			};
		};

		clock@fuse_burn {
			clk-id = <0x27b>;

			rail@vdd_core {
				rail-id = <0x2>;

				opp@0 {
					cvb-coeffs = <0x3f51eb85 0x0 0x0>;
					freq = <0x0 0x124f800>;
				};
			};
		};
	};

	temp-ranges@aotag_for_soc_tr {
		thermzone-id = <0x6>;
		tranges = <0xffffffd8 0x1e 0x19 0x4b 0x46 0x64 0x5f 0x7d 0xffffffd8 0x7d>;
		linux,phandle = <0x6>;
		phandle = <0x6>;
	};

	sku {

		ta795sa {
			valid-sku-ids = <0x0 0x90 0xdc>;
		};
	};

	emc-strap {
		select = <0x8 0x9 0x0 0x0>;
	};

	external-memory-0 {
		compatible = "nvidia,tegra18-emc";
		reg = <0x0 0x2c10000 0x0 0x10000>;
		#address-cells = <0x1>;
		#size-cells = <0x0>;
		linux,phandle = <0x8>;
		phandle = <0x8>;

		emc-table@204000 {
			compatible = "nvidia,tegra18-emc-table";
			nvidia,revision = <0xa>;
			nvidia,dvfs-version = "09_204000_NoCfgVersion_V1.3.8_V4.9";
			clock-frequency = <0x31ce0>;
			nvidia,emc-min-mv = <0x2d0>;
			nvidia,gk20a-min-mv = <0x44c>;
			nvidia,source = "pllp_out0";
			nvidia,src-sel-reg = <0x40008002>;
			nvidia,mem-pll-ssc-control = <0x1>;
			nvidia,needs-training = <0x0>;
			nvidia,training_pattern = <0x0>;
			nvidia,trained = <0x0>;
			nvidia,periodic_training = <0x0>;
			nvidia,trained_dram_clktree_c0d0u0 = <0x0>;
			nvidia,trained_dram_clktree_c0d0u1 = <0x0>;
			nvidia,trained_dram_clktree_c0d1u0 = <0x0>;
			nvidia,trained_dram_clktree_c0d1u1 = <0x0>;
			nvidia,trained_dram_clktree_c1d0u0 = <0x0>;
			nvidia,trained_dram_clktree_c1d0u1 = <0x0>;
			nvidia,trained_dram_clktree_c1d1u0 = <0x0>;
			nvidia,trained_dram_clktree_c1d1u1 = <0x0>;
			nvidia,trained_dram_clktree_c2d0u0 = <0x0>;
			nvidia,trained_dram_clktree_c2d0u1 = <0x0>;
			nvidia,trained_dram_clktree_c2d1u0 = <0x0>;
			nvidia,trained_dram_clktree_c2d1u1 = <0x0>;
			nvidia,trained_dram_clktree_c3d0u0 = <0x0>;
			nvidia,trained_dram_clktree_c3d0u1 = <0x0>;
			nvidia,trained_dram_clktree_c3d1u0 = <0x0>;
			nvidia,trained_dram_clktree_c3d1u1 = <0x0>;
			nvidia,current_dram_clktree_c0d0u0 = <0x0>;
			nvidia,current_dram_clktree_c0d0u1 = <0x0>;
			nvidia,current_dram_clktree_c0d1u0 = <0x0>;
			nvidia,current_dram_clktree_c0d1u1 = <0x0>;
			nvidia,current_dram_clktree_c1d0u0 = <0x0>;
			nvidia,current_dram_clktree_c1d0u1 = <0x0>;
			nvidia,current_dram_clktree_c1d1u0 = <0x0>;
			nvidia,current_dram_clktree_c1d1u1 = <0x0>;
			nvidia,current_dram_clktree_c2d0u0 = <0x0>;
			nvidia,current_dram_clktree_c2d0u1 = <0x0>;
			nvidia,current_dram_clktree_c2d1u0 = <0x0>;
			nvidia,current_dram_clktree_c2d1u1 = <0x0>;
			nvidia,current_dram_clktree_c3d0u0 = <0x0>;
			nvidia,current_dram_clktree_c3d0u1 = <0x0>;
			nvidia,current_dram_clktree_c3d1u0 = <0x0>;
			nvidia,current_dram_clktree_c3d1u1 = <0x0>;
			nvidia,emc_channel_enable = <0xf>;
			nvidia,run_clocks = <0xd>;
			nvidia,tree_margin = <0x1>;
			nvidia,burst-regs-num = <0x92>;
			nvidia,burst-regs-per-ch-num = <0x38>;
			nvidia,burst-pmacro-regs-per-ch-num = <0xa2>;
			nvidia,trim-regs-per-ch-num = <0x14>;
			nvidia,trim-pmacro-regs-per-ch-num = <0x100>;
			nvidia,vref-regs-num = <0x8>;
			nvidia,dram-timing-regs-num = <0x5>;
			nvidia,training-mod-regs-num = <0x28>;
			nvidia,burst-mc-regs-num = <0x25>;
			nvidia,la-scale-regs-num = <0x28>;
			nvidia,emc-ptfv-list = <0x0 0x0 0x0 0x0 0x0 0x0 0x0 0x0 0x0 0x0 0x0 0x0 0x0 0x0 0x0 0x0 0xa 0xa 0xa 0x1>;
			nvidia,emc-registers = <0xd 0x25 0x13 0x0 0x0 0x9 0x4 0xb 0xd 0x8 0xb 0x0 0x4 0x17 0x15 0x17 0x1b 0x0 0x20 0x6 0x6 0x6 0x3 0x0 0x6 0x4 0x2 0x0 0x4 0x8 0xd 0x5 0x6 0x0 0x0 0x2 0x8033131 0xd 0x1 0x80000000 0x10000 0x12 0x18 0x1a 0x16 0x18 0x304 0x0 0xc1 0x8 0x8 0x3 0xa 0x3 0x14 0x5 0x2 0xd 0x27 0x27 0x5 0x5 0x4 0x9 0x5 0x4 0x9 0x48033131 0x31c 0x0 0x9180a00d 0x3a3f 0x0 0x2c00a0 0x8000 0x64 0x80b0000 0x0 0x0 0x0 0x0 0x409 0x8020221f 0x220f40f 0x12 0x64000 0x900cc 0xcc0010 0x33000a 0xc1e00302 0x1f13412f 0x110014 0x101fdd 0x331010 0x804 0x550 0xf3200000 0x713 0x713 0xa 0x20000 0x50037 0x0 0x210 0x3000 0xa000000 0x2000111 0x8 0xd0909 0x156210 0x140404 0x1600 0x0 0x0 0x0 0x30 0x40 0x20 0xefffefff 0xc0c0c0c0 0xc0c0c0c0 0xdcdcdcdc 0xa0a0a0a 0xa0a0a0a 0xa0a0a0a 0x1186033 0x0 0x0 0x18 0xa 0x1a 0x8161414 0x12 0x10000 0x9080 0x7070404 0x40065 0x513801f 0x1f101100 0x14 0x1110fc00 0xf081300 0x1114fc00 0x7000300 0x55553c5a 0x48161414>;
			nvidia,emc-burst-regs-per-ch = <0xfff0000 0xfff0000 0xfff0000 0xfff0000 0xfff0000 0xfff0000 0xfff0000 0xfff0000 0x0 0x0 0x0 0x0 0x880c7272 0x880c7272 0x880c7272 0x880c7272 0x480c7272 0x480c7272 0x480c7272 0x480c7272 0x8c0e6060 0x8c0e6060 0x8c0e6060 0x8c0e6060 0x4c0e6060 0x4c0e6060 0x4c0e6060 0x4c0e6060 0x0 0x0 0x0 0x0 0x0 0x0 0x0 0x0 0x1b 0x1b 0x1b 0x1b 0x1b 0x1b 0x1b 0x1b 0x107240 0x107240 0x107240 0x107240 0x105835 0x105835 0x105835 0x105835 0x107252 0x107252 0x107252 0x107252>;
			nvidia,emc-pmacro-regs-per-ch = <0x130013 0x130013 0x120012 0x110011 0x100010 0x100010 0x140014 0x100010 0x13 0x13 0x0 0x0 0x0 0x0 0x0 0x0 0x0 0x0 0x0 0x0 0x0 0x0 0x0 0x0 0x0 0x0 0x0 0x0 0x0 0x0 0x0 0x0 0x0 0x0 0x0 0x0 0x0 0x0 0x0 0x0 0x0 0x0 0x0 0x0 0x0 0x0 0x0 0x0 0x0 0x0 0x0 0x0 0x0 0x0 0x0 0x0 0x0 0x0 0x0 0x0 0x0 0x0 0x0 0x0 0x0 0x0 0x0 0x0 0x0 0x0 0x0 0x0 0x0 0x0 0x0 0x0 0x0 0x0 0x0 0x0 0x0 0x0 0x0 0x0 0x0 0x0 0x0 0x0 0x0 0x0 0x0 0x0 0x0 0x0 0x0 0x0 0x0 0x0 0x0 0x0 0x0 0x0 0x0 0x0 0x0 0x0 0x460041 0x470044 0x440043 0x460042 0x470048 0x450041 0x48004b 0x460047 0x50009 0x5 0xd0008 0x50000 0x460041 0x470044 0x440043 0x460042 0x470048 0x450041 0x48004b 0x460047 0x50009 0x5 0xd0008 0x50000 0x0 0x0 0x0 0x0 0x0 0x0 0x0 0x0 0x0 0x0 0x0 0x8000000 0x8000000 0x8000000 0x0 0x0 0x8000800 0x800 0x0 0x0 0x0 0x0 0x0 0x0 0x0 0x0 0x0 0x0 0x0 0x0 0x0 0x0>;
			nvidia,emc-shadow-regs-ca-train = <0xd 0x25 0x13 0x0 0x0 0x9 0x4 0xb 0xd 0x8 0xb 0x0 0x4 0x17 0x15 0x17 0x1b 0x0 0x20 0x6 0x6 0x6 0x3 0x0 0x6 0x4 0x2 0x0 0x4 0x8 0xd 0x5 0x6 0x0 0x0 0x2 0x8033131 0xd 0x1 0x80000000 0x10000 0x12 0x18 0x1a 0x16 0x18 0x304 0x0 0xc1 0x8 0x8 0x3 0xa 0x3 0x14 0x5 0x2 0xd 0x27 0x27 0x5 0x5 0x4 0x9 0x5 0x4 0x9 0x48033131 0x31c 0x0 0x9980a00d 0x3a3f 0x0 0x2c00a0 0x8000 0x64 0x80b0000 0x0 0x0 0x0 0x0 0x409 0x8020221f 0x220f40f 0x12 0x64000 0x900cc 0xcc0010 0x33000a 0xc1e00302 0x1f13412f 0x110014 0x101fdd 0x331010 0x804 0x550 0xf3200000 0x713 0x713 0xa 0x20000 0x5058033 0x5050000 0x200 0x3000 0xa000000 0x2000111 0x8 0xd0909 0x156210 0x140404 0x1600 0x0 0x0 0x0 0x30 0x40 0x20 0xefffefff 0xc0c0c0c0 0xc0c0c0c0 0xdcdcdcdc 0xa0a0a0a 0xa0a0a0a 0xa0a0a0a 0x1186033 0x1 0x1f 0x1c 0x8 0x1e 0x8161414 0x10 0x10000 0x19080 0x7070404 0x40065 0x513801f 0x1f101100 0x14 0x1110fc00 0xf081300 0x1114fc00 0x7000300 0x55553c5a 0x48161414>;
			nvidia,emc-shadow-regs-rdwr-train = <0xd 0x25 0x13 0x0 0x0 0x9 0x4 0xe 0xe 0x8 0xb 0x0 0x4 0x17 0x15 0x17 0x1b 0x0 0x20 0x6 0x6 0x6 0x13 0x13 0x6 0x4 0x2 0x0 0x4 0x8 0xd 0x5 0x6 0x30000000 0x30000002 0x2 0x8033131 0xd 0x1 0x80000000 0x40000 0x12 0x18 0x1a 0x16 0x18 0x304 0x0 0xc1 0x8 0x8 0x3 0xa 0x3 0x14 0x5 0x2 0xd 0x27 0x27 0x5 0x5 0x4 0x9 0x5 0x4 0x9 0x48033131 0x31c 0x0 0x9180a00d 0x3a3f 0x0 0x2c00a0 0x8000 0x64 0x80b0000 0x0 0x0 0x0 0x0 0x409 0x8020221f 0x220f40f 0x12 0x64000 0x900cc 0xcc0010 0x33000a 0xc1e00302 0x1f13412f 0x110014 0x101fdd 0x331010 0x804 0x550 0xf3200000 0x713 0x713 0xa 0x20000 0x50037 0x0 0x210 0x3000 0xa000000 0x2000111 0x8 0xd0909 0x156210 0x140404 0x1600 0x0 0x0 0x0 0x30 0x40 0x20 0xefffefff 0xc0c0c0c0 0xc0c0c0c0 0xdcdcdcdc 0xa0a0a0a 0xa0a0a0a 0xa0a0a0a 0x1186033 0x1 0x0 0x18 0xa 0x1a 0x8161414 0x12 0x40000 0xb080 0x7070404 0x40065 0x513801f 0x1f101100 0x14 0x1110fc00 0xf081300 0x1114fc00 0x7000300 0x55553c5a 0x48161414>;
			nvidia,emc-trim-regs-per-ch = <0x0 0x0 0x0 0x0 0x249249 0x249249 0x249249 0x249249 0x249249 0x249249 0x249249 0x249249 0x0 0x0 0x0 0x0 0x0 0x0 0x0 0x0>;
			nvidia,emc-trim-pmacro-regs-per-ch = <0x28282828 0x28282828 0x28282828 0x28282828 0x11111111 0x11111111 0x11111111 0x11111111 0x0 0x0 0x0 0x0 0x0 0x0 0x0 0x0 0x120013 0x110013 0x140010 0x100010 0x0 0x0 0x0 0x0 0x0 0x0 0x0 0x0 0x120013 0x110013 0x140010 0x100010 0x280028 0x280028 0x280028 0x280028 0x280028 0x280028 0x280028 0x280028 0x280028 0x280028 0x280028 0x280028 0x280028 0x280028 0x280028 0x280028 0x0 0x0 0x0 0x0 0x0 0x0 0x0 0x0 0x0 0x0 0x0 0x0 0x0 0x0 0x0 0x0 0x0 0x0 0x0 0x0 0x0 0x0 0x0 0x0 0x0 0x0 0x0 0x0 0x0 0x0 0x0 0x0 0x0 0x0 0x0 0x0 0x0 0x0 0x0 0x0 0x0 0x0 0x0 0x0 0x0 0x0 0x0 0x0 0x0 0x0 0x0 0x0 0x0 0x0 0x0 0x0 0x0 0x0 0x0 0x0 0x0 0x0 0x0 0x0 0x0 0x0 0x0 0x0 0x0 0x0 0x0 0x0 0x0 0x0 0x0 0x0 0x0 0x0 0x0 0x0 0x0 0x0 0x0 0x0 0x0 0x0 0x0 0x0 0x0 0x0 0x0 0x0 0x0 0x0 0x0 0x0 0x0 0x0 0x0 0x0 0x0 0x0 0x0 0x0 0x0 0x0 0x0 0x0 0x0 0x0 0x0 0x0 0x0 0x0 0x0 0x0 0x0 0x0 0x0 0x0 0x0 0x0 0x0 0x0 0x0 0x0 0x0 0x0 0x0 0x0 0x0 0x0 0x0 0x0 0x0 0x0 0x0 0x0 0x0 0x0 0x0 0x0 0x0 0x0 0x0 0x0 0x0 0x0 0x0 0x0 0x0 0x0 0x0 0x0 0x0 0x0 0x0 0x0 0x0 0x0 0x0 0x0 0x0 0x0 0x0 0x0 0x0 0x0 0x0 0x0 0x0 0x0 0x0 0x0 0x0 0x0 0x0 0x0 0x0 0x0 0x0 0x0 0x0 0x0 0x0 0x0 0x0 0x0 0x0 0x0 0x0 0x0 0x0 0x0 0x0 0x0 0x0 0x0 0x0 0x0 0x0 0x0 0x0 0x0 0x0 0x0 0x0 0x0>;
			nvidia,emc-vref-regs = <0x0 0x0 0x0 0x0 0x0 0x0 0x0 0x0>;
			nvidia,emc-dram-timing-regs = <0x12 0x104 0xb4 0x18 0x6>;
			nvidia,emc-zqcal-param-regs = <0x0 0x0 0x0 0x0 0xf4240 0x960>;
			nvidia,emc-opt-regs = <0x0 0x0 0x0 0x1 0x0 0x0 0x1 0x0>;
			nvidia,emc-training-mod-regs = <0x0 0x0 0x0 0x0 0x0 0x0 0x0 0x0 0x0 0x0 0x0 0x0 0x0 0x0 0x0 0x0 0x0 0x0 0x0 0x0 0x0 0x0 0x0 0x0 0x0 0x0 0x0 0x0 0x0 0x0 0x0 0x0 0x0 0x0 0x0 0x0 0x0 0x0 0x0 0x0>;
			nvidia,emc-save-restore-mod-regs = <0x0 0x0 0x0 0x0 0x0 0x0 0x0 0x0 0x0 0x0 0x0 0x0 0x0 0x0 0x0 0x0>;
			nvidia,emc-burst-mc-regs = <0x8000001 0x800000e8 0x800000d8 0xa1020 0x80001028 0x1 0x0 0x3 0x1 0x2 0x1 0x2 0x5 0x2 0x1 0x4 0x8 0x5 0x4 0x2020001 0x30201 0x71c30504 0x70000f0f 0x0 0x3f0000 0x3f0000 0x20400000 0x40004 0x80001a 0x80001a 0x80001a 0x80001a 0x80001a 0x80001a 0x80001a 0x80001a 0x80001a>;
			nvidia,emc-la-scale-regs = <0x1e 0x24c 0xff00f6 0xff00f6 0xff00bd 0xff00ff 0xff00ff 0xff00ff 0xff00f1 0xff0004 0xbd 0xff00fb 0xff00fb 0xff00b1 0xff0073 0xff00fb 0xff 0xfa 0xff00ff 0xff 0xce 0xce 0xff00ff 0xff000a 0xff00bd 0xff000a 0xff00bc 0xff00f8 0xff000a 0xff00bd 0xff00f7 0xff0050 0xff0024 0xff00f5 0xff00fb 0xff000a 0xff00bd 0xff00f9 0xff00bd 0xff00f8>;
			nvidia,emc-fdr-sequence-regs = <0x14 0x18 0x1f4 0x1 0x0 0x0 0x1c>;
			nvidia,emc-debug-regs = <0x21 0x0 0x0 0x0 0x0 0x0 0x0>;
			nvidia,emc-mempll-spread-spectrum-regs = <0xc0000000 0x40082fb 0x10400 0xc0000000 0x40082fb 0x10400 0xc0000000 0x40082fb 0x10400 0xc0000000 0x40082fb 0x10400>;
			nvidia,min-mrs-wait = <0x10>;
			nvidia,bg-ilvl-ctrl = <0x0>;
			nvidia,emc-mrw = <0x8010004>;
			nvidia,emc-mrw2 = <0x8020000>;
			nvidia,emc-mrw3 = <0x80d0000>;
			nvidia,emc-mrw4 = <0xc0000000>;
			nvidia,emc-mrw9-0 = <0xc0e6060>;
			nvidia,emc-mrw9-2 = <0xc0e6060>;
			nvidia,emc-mrs = <0x0>;
			nvidia,emc-emrs = <0x0>;
			nvidia,emc-emrs2 = <0x0>;
			nvidia,emc-auto-cal-config = <0xa01a51d8>;
			nvidia,emc-auto-cal-config2 = <0x5500000>;
			nvidia,emc-auto-cal-config3-0 = <0x880000>;
			nvidia,emc-auto-cal-config3-2 = <0x880000>;
			nvidia,emc-auto-cal-config4-0 = <0x880000>;
			nvidia,emc-auto-cal-config4-2 = <0x880000>;
			nvidia,emc-auto-cal-config5-0 = <0x880000>;
			nvidia,emc-auto-cal-config5-2 = <0x880000>;
			nvidia,emc-auto-cal-config6-0 = <0x880000>;
			nvidia,emc-auto-cal-config6-2 = <0x880000>;
			nvidia,emc-auto-cal-config7-0 = <0x880000>;
			nvidia,emc-auto-cal-config7-2 = <0x880000>;
			nvidia,emc-auto-cal-config8-0 = <0x880000>;
			nvidia,emc-auto-cal-config8-2 = <0x880000>;
			nvidia,emc-cfg-2 = <0x110825>;
			nvidia,emc-sel-dpd-ctrl = <0x40008>;
			nvidia,emc-fdpd-ctrl-cmd-no-ramp = <0x1>;
			nvidia,dll-clk-src = <0x40008002>;
			nvidia,clk-out-enb-x-0-clk-enb-emc-dll = <0x1>;
			nvidia,emc-clock-latency-change = <0xd5c>;
		};

		emc-table@1600000 {
			compatible = "nvidia,tegra18-emc-table";
			nvidia,revision = <0xa>;
			nvidia,dvfs-version = "09_1600000_NoCfgVersion_V1.3.8_V4.9";
			clock-frequency = <0x186a00>;
			nvidia,emc-min-mv = <0x35c>;
			nvidia,gk20a-min-mv = <0x44c>;
			nvidia,source = "pllm_ud";
			nvidia,src-sel-reg = <0x80008000>;
			nvidia,mem-pll-ssc-control = <0x1>;
			nvidia,needs-training = <0x2f0>;
			nvidia,training_pattern = <0x0>;
			nvidia,trained = <0x0>;
			nvidia,periodic_training = <0x1>;
			nvidia,trained_dram_clktree_c0d0u0 = <0x0>;
			nvidia,trained_dram_clktree_c0d0u1 = <0x0>;
			nvidia,trained_dram_clktree_c0d1u0 = <0x0>;
			nvidia,trained_dram_clktree_c0d1u1 = <0x0>;
			nvidia,trained_dram_clktree_c1d0u0 = <0x0>;
			nvidia,trained_dram_clktree_c1d0u1 = <0x0>;
			nvidia,trained_dram_clktree_c1d1u0 = <0x0>;
			nvidia,trained_dram_clktree_c1d1u1 = <0x0>;
			nvidia,trained_dram_clktree_c2d0u0 = <0x0>;
			nvidia,trained_dram_clktree_c2d0u1 = <0x0>;
			nvidia,trained_dram_clktree_c2d1u0 = <0x0>;
			nvidia,trained_dram_clktree_c2d1u1 = <0x0>;
			nvidia,trained_dram_clktree_c3d0u0 = <0x0>;
			nvidia,trained_dram_clktree_c3d0u1 = <0x0>;
			nvidia,trained_dram_clktree_c3d1u0 = <0x0>;
			nvidia,trained_dram_clktree_c3d1u1 = <0x0>;
			nvidia,current_dram_clktree_c0d0u0 = <0x0>;
			nvidia,current_dram_clktree_c0d0u1 = <0x0>;
			nvidia,current_dram_clktree_c0d1u0 = <0x0>;
			nvidia,current_dram_clktree_c0d1u1 = <0x0>;
			nvidia,current_dram_clktree_c1d0u0 = <0x0>;
			nvidia,current_dram_clktree_c1d0u1 = <0x0>;
			nvidia,current_dram_clktree_c1d1u0 = <0x0>;
			nvidia,current_dram_clktree_c1d1u1 = <0x0>;
			nvidia,current_dram_clktree_c2d0u0 = <0x0>;
			nvidia,current_dram_clktree_c2d0u1 = <0x0>;
			nvidia,current_dram_clktree_c2d1u0 = <0x0>;
			nvidia,current_dram_clktree_c2d1u1 = <0x0>;
			nvidia,current_dram_clktree_c3d0u0 = <0x0>;
			nvidia,current_dram_clktree_c3d0u1 = <0x0>;
			nvidia,current_dram_clktree_c3d1u0 = <0x0>;
			nvidia,current_dram_clktree_c3d1u1 = <0x0>;
			nvidia,emc_channel_enable = <0xf>;
			nvidia,run_clocks = <0x40>;
			nvidia,tree_margin = <0x1>;
			nvidia,burst-regs-num = <0x92>;
			nvidia,burst-regs-per-ch-num = <0x38>;
			nvidia,burst-pmacro-regs-per-ch-num = <0xa2>;
			nvidia,trim-regs-per-ch-num = <0x14>;
			nvidia,trim-pmacro-regs-per-ch-num = <0x100>;
			nvidia,vref-regs-num = <0x8>;
			nvidia,dram-timing-regs-num = <0x5>;
			nvidia,training-mod-regs-num = <0x28>;
			nvidia,burst-mc-regs-num = <0x25>;
			nvidia,la-scale-regs-num = <0x28>;
			nvidia,emc-ptfv-list = <0x0 0x0 0x0 0x0 0x0 0x0 0x0 0x0 0x0 0x0 0x0 0x0 0x0 0x0 0x0 0x0 0xa 0xa 0xa 0x1>;
			nvidia,emc-registers = <0x60 0x120 0x90 0x0 0x0 0x44 0x1d 0x2a 0x21 0xc 0x2d 0x0 0x4 0x3a 0x23 0x3e 0x41 0x0 0x20 0x1d 0x1d 0x10 0x17 0x16 0x6 0xe 0xc 0xa 0xe 0x8 0xd 0x24 0x9 0x1000001c 0x10000002 0x14 0x803f1f1 0x1d 0x1 0x80000000 0x6000c 0x34 0x3a 0x3c 0x38 0x3a 0x1820 0x0 0x608 0x10 0x10 0x3 0x17 0x3 0x38 0xe 0x2 0x2e 0x12c 0x12c 0xd 0x18 0xc 0x40 0x22 0x4 0x14 0x4803f1f1 0x1860 0x0 0x9980a00d 0x3bff 0x0 0xc00001bb 0x8000 0x64 0x80b6666 0x0 0x0 0x0 0x0 0x409 0x8020221f 0x220f40f 0x12 0x64000 0x310640 0x640002f 0x1900017 0xc1e00309 0x1f13612f 0x200014 0x101fdd 0x331010 0x80d 0x550 0xf3200000 0x308c 0x308c 0x2c 0x20000 0x33 0x0 0x211 0x3000 0x2000000 0x2000101 0x0 0xd0909 0x156210 0x140404 0x1fff 0x0 0x80 0x0 0x30 0x40 0x20 0xefff2010 0x0 0x0 0xdcdcdcdc 0xa0a0a0a 0xa0a0a0a 0xa0a0a0a 0x1186190 0x0 0x0 0x3a 0x2c 0x3c 0x8161414 0x34 0x6000c 0x9080 0x7070404 0x40320 0x513801f 0x1f101100 0x14 0x1110fc00 0xf085300 0x1114fc00 0x7004300 0x55553c5a 0x48161414>;
			nvidia,emc-burst-regs-per-ch = <0xfff0000 0xfff0000 0xfff0000 0xfff0000 0xfff0000 0xfff0000 0xfff0000 0xfff0000 0x0 0x0 0x0 0x0 0x880c4848 0x880c4848 0x880c4848 0x880c4848 0x480c4848 0x480c4848 0x480c4848 0x480c4848 0x8c0e4848 0x8c0e4848 0x8c0e4848 0x8c0e4848 0x4c0e4848 0x4c0e4848 0x4c0e4848 0x4c0e4848 0x0 0x0 0x0 0x0 0x0 0x0 0x0 0x0 0x1b 0x1b 0x1b 0x1b 0x1b 0x1b 0x1b 0x1b 0x103200 0x103200 0x103200 0x103200 0x102c00 0x102c00 0x102c00 0x102c00 0x102900 0x102900 0x102900 0x102900>;
			nvidia,emc-pmacro-regs-per-ch = <0xb000b 0xb000b 0xb000b 0xa000a 0x90009 0xa000a 0xc000c 0x90009 0xb 0xb 0x0 0x0 0x0 0x0 0x0 0x0 0x0 0x0 0x0 0x0 0x0 0x0 0x0 0x0 0x0 0x0 0x0 0x0 0x0 0x0 0x0 0x0 0x0 0x0 0x0 0x0 0x0 0x0 0x0 0x0 0x0 0x0 0x0 0x0 0x0 0x0 0x0 0x0 0x0 0x0 0x0 0x0 0x0 0x0 0x0 0x0 0x0 0x0 0x0 0x0 0x0 0x0 0x0 0x0 0x0 0x0 0x0 0x0 0x0 0x0 0x0 0x0 0x0 0x0 0x0 0x0 0x0 0x0 0x0 0x0 0x0 0x0 0x0 0x0 0x0 0x0 0x0 0x0 0x0 0x0 0x0 0x0 0x0 0x0 0x0 0x0 0x0 0x0 0x0 0x0 0x0 0x0 0x0 0x0 0x0 0x0 0x5 0x5 0x7 0x2000a 0x5 0x8 0x2 0x5 0x30005 0x3 0x80005 0x30000 0x5 0x5 0x7 0x2000a 0x5 0x8 0x2 0x5 0x30005 0x3 0x80005 0x30000 0x0 0x0 0x0 0x0 0x0 0x0 0x0 0x0 0x0 0x0 0x0 0x8000000 0x8000000 0x8000000 0x0 0x0 0x8000800 0x800 0x0 0x0 0x0 0x0 0x0 0x0 0x0 0x0 0x0 0x0 0x0 0x0 0x0 0x0>;
			nvidia,emc-shadow-regs-ca-train = <0x60 0x120 0x90 0x0 0x0 0x44 0x1d 0x2a 0x21 0xc 0x2d 0x0 0x4 0x3a 0x23 0x3e 0x41 0x0 0x20 0x1d 0x1d 0x10 0x17 0x16 0x6 0xe 0xc 0xa 0xe 0x8 0xd 0x24 0x9 0x1000001c 0x10000002 0x14 0x803f1f1 0x1d 0x1 0x80000000 0x6000c 0x34 0x3a 0x3c 0x38 0x3a 0x1820 0x0 0x608 0x10 0x10 0x3 0x17 0x3 0x38 0xe 0x2 0x2e 0x12c 0x12c 0xd 0x18 0xc 0x40 0x22 0x4 0x14 0x4803f1f1 0x1860 0x0 0x9980a00d 0x3bff 0x0 0xc00001bb 0x8000 0x64 0x80b6666 0x0 0x0 0x0 0x0 0x409 0x8020221f 0x220f40f 0x12 0x64000 0x310640 0x640002f 0x1900017 0xc1e00309 0x1f13612f 0x200014 0x101fdd 0x331010 0x80d 0x550 0xf3200000 0x308c 0x308c 0x2c 0x20000 0x8033 0x0 0x200 0x3000 0x2000000 0x2000101 0x0 0xd0909 0x156210 0x140404 0x1fff 0x0 0x80 0x0 0x30 0x40 0x20 0xefff2010 0x0 0x0 0xdcdcdcdc 0xa0a0a0a 0xa0a0a0a 0xa0a0a0a 0x1186190 0x1 0x1f 0x40 0x2c 0x42 0x8161414 0x34 0x6000c 0x19080 0x7070404 0x40320 0x513801f 0x1f101100 0x14 0x1110fc00 0xf085300 0x1114fc00 0x7004300 0x55553c5a 0x48161414>;
			nvidia,emc-shadow-regs-rdwr-train = <0x60 0x120 0x90 0x0 0x0 0x44 0x1d 0x2a 0x22 0xc 0x2d 0x0 0x4 0x3a 0x23 0x3e 0x41 0x0 0x20 0x1d 0x1d 0x10 0x17 0x16 0x6 0xe 0xc 0xa 0xe 0x8 0xd 0x24 0x9 0x1000001c 0x10000002 0x14 0x803f1f1 0x1d 0x1 0x80000000 0x6000c 0x34 0x3a 0x3c 0x38 0x3a 0x1820 0x0 0x608 0x10 0x10 0x3 0x17 0x3 0x38 0xe 0x2 0x2e 0x12c 0x12c 0xd 0x18 0xc 0x40 0x22 0x4 0x14 0x4803f1f1 0x1860 0x0 0x9980a00d 0x3bff 0x0 0xc00001bb 0x8000 0x64 0x80b6666 0x0 0x0 0x0 0x0 0x409 0x8020221f 0x220f40f 0x12 0x64000 0x310640 0x640002f 0x1900017 0xc1e00309 0x1f13612f 0x200014 0x101fdd 0x331010 0x80d 0x550 0xf3200000 0x308c 0x308c 0x2c 0x20000 0x33 0x0 0x211 0x3000 0x2000000 0x2000101 0x0 0xd0909 0x156210 0x140404 0x1fff 0x0 0x80 0x0 0x30 0x40 0x20 0xefff2010 0x0 0x0 0xdcdcdcdc 0xa0a0a0a 0xa0a0a0a 0xa0a0a0a 0x1186190 0x1 0x0 0x3a 0x2c 0x3c 0x8161414 0x34 0x6000c 0xb080 0x7070404 0x40320 0x513801f 0x1f101100 0x14 0x1110fc00 0xf085300 0x1114fc00 0x7004300 0x55553c5a 0x48161414>;
			nvidia,emc-trim-regs-per-ch = <0x0 0x0 0x0 0x0 0x0 0x0 0x0 0x0 0x0 0x0 0x0 0x0 0x0 0x0 0x0 0x0 0x0 0x0 0x0 0x0>;
			nvidia,emc-trim-pmacro-regs-per-ch = <0x11111111 0x11111111 0x11111111 0x11111111 0x11111111 0x11111111 0x11111111 0x11111111 0x220024 0x230026 0x210027 0x240029 0x230029 0x210028 0x230027 0x220027 0xb000b 0xa000b 0xc0009 0x9000a 0x220024 0x230026 0x210027 0x240029 0x230029 0x210028 0x230027 0x220027 0xb000b 0xa000b 0xc0009 0x9000a 0x200020 0x200020 0x200020 0x200020 0x200020 0x200020 0x200020 0x200020 0x200020 0x200020 0x200020 0x200020 0x200020 0x200020 0x200020 0x200020 0x0 0x0 0x0 0x0 0x0 0x0 0x0 0x0 0x0 0x0 0x0 0x0 0x0 0x0 0x0 0x0 0x0 0x0 0x0 0x0 0x0 0x0 0x0 0x0 0x0 0x0 0x0 0x0 0x0 0x0 0x0 0x0 0x0 0x0 0x0 0x0 0x0 0x0 0x0 0x0 0x0 0x0 0x0 0x0 0x0 0x0 0x0 0x0 0x0 0x0 0x0 0x0 0x0 0x0 0x0 0x0 0x0 0x0 0x0 0x0 0x0 0x0 0x0 0x0 0x0 0x0 0x0 0x0 0x0 0x0 0x0 0x0 0x0 0x0 0x0 0x0 0x0 0x0 0x0 0x0 0x0 0x0 0x0 0x0 0x0 0x0 0x0 0x0 0x0 0x0 0x0 0x0 0x0 0x0 0x0 0x0 0x0 0x0 0x0 0x0 0x0 0x0 0x0 0x0 0x0 0x0 0x0 0x0 0x0 0x0 0x0 0x0 0x0 0x0 0x0 0x0 0x0 0x0 0x0 0x0 0x0 0x0 0x0 0x0 0x0 0x0 0x0 0x0 0x0 0x0 0x0 0x0 0x0 0x0 0x0 0x0 0x0 0x0 0x0 0x0 0x0 0x0 0x0 0x0 0x0 0x0 0x0 0x0 0x0 0x0 0x0 0x0 0x0 0x0 0x0 0x0 0x0 0x0 0x0 0x0 0x0 0x0 0x0 0x0 0x0 0x0 0x0 0x0 0x0 0x0 0x0 0x0 0x0 0x0 0x0 0x0 0x0 0x0 0x0 0x0 0x0 0x0 0x0 0x0 0x0 0x0 0x0 0x0 0x0 0x0 0x0 0x0 0x0 0x0 0x0 0x0 0x0 0x0 0x0 0x0 0x0 0x0 0x0 0x0 0x0 0x0 0x0 0x0>;
			nvidia,emc-vref-regs = <0x0 0x0 0x0 0x0 0x0 0x0 0x0 0x0>;
			nvidia,emc-dram-timing-regs = <0x12 0x104 0xb4 0x7 0x20>;
			nvidia,emc-zqcal-param-regs = <0x0 0x0 0x0 0x0 0xf4240 0x960>;
			nvidia,emc-opt-regs = <0x0 0x0 0x0 0x1 0x0 0x0 0x1 0x0>;
			nvidia,emc-training-mod-regs = <0x0 0x0 0x0 0x0 0x0 0x0 0x0 0x0 0x0 0x0 0x0 0x0 0x0 0x0 0x0 0x0 0x0 0x0 0x0 0x0 0x0 0x0 0x0 0x0 0x0 0x0 0x0 0x0 0x0 0x0 0x0 0x0 0x0 0x0 0x0 0x0 0x0 0x0 0x0 0x0>;
			nvidia,emc-save-restore-mod-regs = <0x0 0x0 0x0 0x0 0x0 0x0 0x0 0x0 0x0 0x0 0x0 0x0 0x0 0x0 0x0 0x0>;
			nvidia,emc-burst-mc-regs = <0xc 0x80000100 0x800000f0 0xa1020 0x80001028 0x6 0x7 0x18 0xf 0xf 0x3 0x3 0xd 0x7 0x7 0xc 0x8 0xa 0x23 0x5060303 0xd080c 0x718c2419 0x70000f0f 0x0 0x3f0000 0x3f0000 0x20400000 0x40004 0x80001a 0x80001a 0x80001a 0x80001a 0x80001a 0x80001a 0x80001a 0x80001a 0x80001a>;
			nvidia,emc-la-scale-regs = <0xe7 0x1203 0x80007b 0x80007b 0x8000bd 0x8000ff 0x8000ff 0x8000ff 0x8000f1 0x800004 0xbd 0x800020 0x800020 0x800023 0x800023 0x800020 0x80 0x20 0x800080 0x80 0x64e 0x64e 0x800021 0x80000a 0x8000bd 0x80000a 0x8000bc 0x80007c 0x80000a 0x8000bd 0x800020 0x800050 0x800024 0x80001f 0x800039 0x80000a 0x8000bd 0x800020 0x8000bd 0x800020>;
			nvidia,emc-fdr-sequence-regs = <0x14 0x18 0x1f4 0x1 0x1b 0x19 0x0>;
			nvidia,emc-debug-regs = <0x21 0x0 0x0 0x0 0x0 0x0 0x0>;
			nvidia,emc-mempll-spread-spectrum-regs = <0xc0000000 0xfaabf2ab 0x7faab 0xc0000000 0xfaabf2ab 0x7faab 0xc0000000 0xfaabf2ab 0x7faab 0xc0000000 0xfaabf2ab 0x7faab>;
			nvidia,min-mrs-wait = <0x2f>;
			nvidia,bg-ilvl-ctrl = <0x0>;
			nvidia,emc-mrw = <0x8010054>;
			nvidia,emc-mrw2 = <0x802002d>;
			nvidia,emc-mrw3 = <0x80d0000>;
			nvidia,emc-mrw4 = <0xc0000000>;
			nvidia,emc-mrw9-0 = <0xc0e4848>;
			nvidia,emc-mrw9-2 = <0xc0e4848>;
			nvidia,emc-mrs = <0x0>;
			nvidia,emc-emrs = <0x0>;
			nvidia,emc-emrs2 = <0x0>;
			nvidia,emc-auto-cal-config = <0xa01a51d8>;
			nvidia,emc-auto-cal-config2 = <0x5500000>;
			nvidia,emc-auto-cal-config3-0 = <0x880000>;
			nvidia,emc-auto-cal-config3-2 = <0x880000>;
			nvidia,emc-auto-cal-config4-0 = <0x880000>;
			nvidia,emc-auto-cal-config4-2 = <0x880000>;
			nvidia,emc-auto-cal-config5-0 = <0x880000>;
			nvidia,emc-auto-cal-config5-2 = <0x880000>;
			nvidia,emc-auto-cal-config6-0 = <0x880000>;
			nvidia,emc-auto-cal-config6-2 = <0x880000>;
			nvidia,emc-auto-cal-config7-0 = <0x880000>;
			nvidia,emc-auto-cal-config7-2 = <0x880000>;
			nvidia,emc-auto-cal-config8-0 = <0x880000>;
			nvidia,emc-auto-cal-config8-2 = <0x880000>;
			nvidia,emc-cfg-2 = <0x110835>;
			nvidia,emc-sel-dpd-ctrl = <0x40000>;
			nvidia,emc-fdpd-ctrl-cmd-no-ramp = <0x0>;
			nvidia,dll-clk-src = <0x80008000>;
			nvidia,clk-out-enb-x-0-clk-enb-emc-dll = <0x0>;
			nvidia,emc-clock-latency-change = <0x49c>;
		};

		emc-table-derated@204000 {
			compatible = "nvidia,tegra18-emc-table-derated";
			nvidia,revision = <0xa>;
			nvidia,dvfs-version = "09_204000_NoCfgVersion_V1.3.8_V4.9";
			clock-frequency = <0x31ce0>;
			nvidia,emc-min-mv = <0x2d0>;
			nvidia,gk20a-min-mv = <0x44c>;
			nvidia,source = "pllp_out0";
			nvidia,src-sel-reg = <0x40008002>;
			nvidia,mem-pll-ssc-control = <0x1>;
			nvidia,needs-training = <0x0>;
			nvidia,training_pattern = <0x0>;
			nvidia,trained = <0x0>;
			nvidia,periodic_training = <0x0>;
			nvidia,trained_dram_clktree_c0d0u0 = <0x0>;
			nvidia,trained_dram_clktree_c0d0u1 = <0x0>;
			nvidia,trained_dram_clktree_c0d1u0 = <0x0>;
			nvidia,trained_dram_clktree_c0d1u1 = <0x0>;
			nvidia,trained_dram_clktree_c1d0u0 = <0x0>;
			nvidia,trained_dram_clktree_c1d0u1 = <0x0>;
			nvidia,trained_dram_clktree_c1d1u0 = <0x0>;
			nvidia,trained_dram_clktree_c1d1u1 = <0x0>;
			nvidia,trained_dram_clktree_c2d0u0 = <0x0>;
			nvidia,trained_dram_clktree_c2d0u1 = <0x0>;
			nvidia,trained_dram_clktree_c2d1u0 = <0x0>;
			nvidia,trained_dram_clktree_c2d1u1 = <0x0>;
			nvidia,trained_dram_clktree_c3d0u0 = <0x0>;
			nvidia,trained_dram_clktree_c3d0u1 = <0x0>;
			nvidia,trained_dram_clktree_c3d1u0 = <0x0>;
			nvidia,trained_dram_clktree_c3d1u1 = <0x0>;
			nvidia,current_dram_clktree_c0d0u0 = <0x0>;
			nvidia,current_dram_clktree_c0d0u1 = <0x0>;
			nvidia,current_dram_clktree_c0d1u0 = <0x0>;
			nvidia,current_dram_clktree_c0d1u1 = <0x0>;
			nvidia,current_dram_clktree_c1d0u0 = <0x0>;
			nvidia,current_dram_clktree_c1d0u1 = <0x0>;
			nvidia,current_dram_clktree_c1d1u0 = <0x0>;
			nvidia,current_dram_clktree_c1d1u1 = <0x0>;
			nvidia,current_dram_clktree_c2d0u0 = <0x0>;
			nvidia,current_dram_clktree_c2d0u1 = <0x0>;
			nvidia,current_dram_clktree_c2d1u0 = <0x0>;
			nvidia,current_dram_clktree_c2d1u1 = <0x0>;
			nvidia,current_dram_clktree_c3d0u0 = <0x0>;
			nvidia,current_dram_clktree_c3d0u1 = <0x0>;
			nvidia,current_dram_clktree_c3d1u0 = <0x0>;
			nvidia,current_dram_clktree_c3d1u1 = <0x0>;
			nvidia,emc_channel_enable = <0xf>;
			nvidia,run_clocks = <0xd>;
			nvidia,tree_margin = <0x1>;
			nvidia,burst-regs-num = <0x92>;
			nvidia,burst-regs-per-ch-num = <0x38>;
			nvidia,burst-pmacro-regs-per-ch-num = <0xa2>;
			nvidia,trim-regs-per-ch-num = <0x14>;
			nvidia,trim-pmacro-regs-per-ch-num = <0x100>;
			nvidia,vref-regs-num = <0x8>;
			nvidia,dram-timing-regs-num = <0x5>;
			nvidia,training-mod-regs-num = <0x28>;
			nvidia,burst-mc-regs-num = <0x25>;
			nvidia,la-scale-regs-num = <0x28>;
			nvidia,emc-ptfv-list = <0x0 0x0 0x0 0x0 0x0 0x0 0x0 0x0 0x0 0x0 0x0 0x0 0x0 0x0 0x0 0x0 0xa 0xa 0xa 0x1>;
			nvidia,emc-registers = <0xd 0x25 0x13 0x0 0x0 0x9 0x5 0xb 0xd 0x8 0xb 0x0 0x4 0x17 0x15 0x17 0x1b 0x0 0x20 0x6 0x6 0x6 0x3 0x0 0x6 0x4 0x2 0x0 0x4 0x8 0xd 0x5 0x6 0x0 0x0 0x2 0x8033131 0xd 0x1 0x80000000 0x10000 0x12 0x18 0x1a 0x16 0x18 0xc1 0x0 0x30 0x8 0x8 0x3 0xa 0x3 0x14 0x5 0x2 0xe 0x27 0x27 0x5 0x5 0x4 0x9 0x5 0x4 0x9 0x48033131 0x31c 0x0 0x9180a00d 0x3a3f 0x0 0x2c00a0 0x8000 0x64 0x80b0000 0x0 0x0 0x0 0x0 0x409 0x8020221f 0x220f40f 0x12 0x64000 0x900cc 0xcc0010 0x33000a 0xc1e00302 0x1f13412f 0x110014 0x101fdd 0x331010 0x804 0x550 0xf3200000 0x287 0x287 0xa 0x20000 0x50037 0x0 0x210 0x3000 0xa000000 0x2000111 0x8 0xd0909 0x156210 0x140404 0x1600 0x0 0x0 0x0 0x30 0x40 0x20 0xefffefff 0xc0c0c0c0 0xc0c0c0c0 0xdcdcdcdc 0xa0a0a0a 0xa0a0a0a 0xa0a0a0a 0x1186033 0x0 0x0 0x18 0xa 0x1a 0x8161414 0x12 0x10000 0x9080 0x7070404 0x40065 0x513801f 0x1f101100 0x14 0x1110fc00 0xf081300 0x1114fc00 0x7000300 0x55553c5a 0x48161414>;
			nvidia,emc-burst-regs-per-ch = <0xfff0000 0xfff0000 0xfff0000 0xfff0000 0xfff0000 0xfff0000 0xfff0000 0xfff0000 0x0 0x0 0x0 0x0 0x880c7272 0x880c7272 0x880c7272 0x880c7272 0x480c7272 0x480c7272 0x480c7272 0x480c7272 0x8c0e6060 0x8c0e6060 0x8c0e6060 0x8c0e6060 0x4c0e6060 0x4c0e6060 0x4c0e6060 0x4c0e6060 0x0 0x0 0x0 0x0 0x0 0x0 0x0 0x0 0x1b 0x1b 0x1b 0x1b 0x1b 0x1b 0x1b 0x1b 0x107240 0x107240 0x107240 0x107240 0x105835 0x105835 0x105835 0x105835 0x107252 0x107252 0x107252 0x107252>;
			nvidia,emc-pmacro-regs-per-ch = <0x130013 0x130013 0x120012 0x110011 0x100010 0x100010 0x140014 0x100010 0x13 0x13 0x0 0x0 0x0 0x0 0x0 0x0 0x0 0x0 0x0 0x0 0x0 0x0 0x0 0x0 0x0 0x0 0x0 0x0 0x0 0x0 0x0 0x0 0x0 0x0 0x0 0x0 0x0 0x0 0x0 0x0 0x0 0x0 0x0 0x0 0x0 0x0 0x0 0x0 0x0 0x0 0x0 0x0 0x0 0x0 0x0 0x0 0x0 0x0 0x0 0x0 0x0 0x0 0x0 0x0 0x0 0x0 0x0 0x0 0x0 0x0 0x0 0x0 0x0 0x0 0x0 0x0 0x0 0x0 0x0 0x0 0x0 0x0 0x0 0x0 0x0 0x0 0x0 0x0 0x0 0x0 0x0 0x0 0x0 0x0 0x0 0x0 0x0 0x0 0x0 0x0 0x0 0x0 0x0 0x0 0x0 0x0 0x460041 0x470044 0x440043 0x460042 0x470048 0x450041 0x48004b 0x460047 0x50009 0x5 0xd0008 0x50000 0x460041 0x470044 0x440043 0x460042 0x470048 0x450041 0x48004b 0x460047 0x50009 0x5 0xd0008 0x50000 0x0 0x0 0x0 0x0 0x0 0x0 0x0 0x0 0x0 0x0 0x0 0x8000000 0x8000000 0x8000000 0x0 0x0 0x8000800 0x800 0x0 0x0 0x0 0x0 0x0 0x0 0x0 0x0 0x0 0x0 0x0 0x0 0x0 0x0>;
			nvidia,emc-shadow-regs-ca-train = <0xd 0x25 0x13 0x0 0x0 0x9 0x5 0xb 0xd 0x8 0xb 0x0 0x4 0x17 0x15 0x17 0x1b 0x0 0x20 0x6 0x6 0x6 0x3 0x0 0x6 0x4 0x2 0x0 0x4 0x8 0xd 0x5 0x6 0x0 0x0 0x2 0x8033131 0xd 0x1 0x80000000 0x10000 0x12 0x18 0x1a 0x16 0x18 0xc1 0x0 0x30 0x8 0x8 0x3 0xa 0x3 0x14 0x5 0x2 0xe 0x27 0x27 0x5 0x5 0x4 0x9 0x5 0x4 0x9 0x48033131 0x31c 0x0 0x9980a00d 0x3a3f 0x0 0x2c00a0 0x8000 0x64 0x80b0000 0x0 0x0 0x0 0x0 0x409 0x8020221f 0x220f40f 0x12 0x64000 0x900cc 0xcc0010 0x33000a 0xc1e00302 0x1f13412f 0x110014 0x101fdd 0x331010 0x804 0x550 0xf3200000 0x287 0x287 0xa 0x20000 0x5058033 0x5050000 0x200 0x3000 0xa000000 0x2000111 0x8 0xd0909 0x156210 0x140404 0x1600 0x0 0x0 0x0 0x30 0x40 0x20 0xefffefff 0xc0c0c0c0 0xc0c0c0c0 0xdcdcdcdc 0xa0a0a0a 0xa0a0a0a 0xa0a0a0a 0x1186033 0x1 0x1f 0x1c 0x8 0x1e 0x8161414 0x10 0x10000 0x19080 0x7070404 0x40065 0x513801f 0x1f101100 0x14 0x1110fc00 0xf081300 0x1114fc00 0x7000300 0x55553c5a 0x48161414>;
			nvidia,emc-shadow-regs-rdwr-train = <0xd 0x25 0x13 0x0 0x0 0x9 0x5 0xe 0xe 0x8 0xb 0x0 0x4 0x17 0x15 0x17 0x1b 0x0 0x20 0x6 0x6 0x6 0x13 0x13 0x6 0x4 0x2 0x0 0x4 0x8 0xd 0x5 0x6 0x30000000 0x30000002 0x2 0x8033131 0xd 0x1 0x80000000 0x40000 0x12 0x18 0x1a 0x16 0x18 0xc1 0x0 0x30 0x8 0x8 0x3 0xa 0x3 0x14 0x5 0x2 0xe 0x27 0x27 0x5 0x5 0x4 0x9 0x5 0x4 0x9 0x48033131 0x31c 0x0 0x9180a00d 0x3a3f 0x0 0x2c00a0 0x8000 0x64 0x80b0000 0x0 0x0 0x0 0x0 0x409 0x8020221f 0x220f40f 0x12 0x64000 0x900cc 0xcc0010 0x33000a 0xc1e00302 0x1f13412f 0x110014 0x101fdd 0x331010 0x804 0x550 0xf3200000 0x287 0x287 0xa 0x20000 0x50037 0x0 0x210 0x3000 0xa000000 0x2000111 0x8 0xd0909 0x156210 0x140404 0x1600 0x0 0x0 0x0 0x30 0x40 0x20 0xefffefff 0xc0c0c0c0 0xc0c0c0c0 0xdcdcdcdc 0xa0a0a0a 0xa0a0a0a 0xa0a0a0a 0x1186033 0x1 0x0 0x18 0xa 0x1a 0x8161414 0x12 0x40000 0xb080 0x7070404 0x40065 0x513801f 0x1f101100 0x14 0x1110fc00 0xf081300 0x1114fc00 0x7000300 0x55553c5a 0x48161414>;
			nvidia,emc-trim-regs-per-ch = <0x0 0x0 0x0 0x0 0x249249 0x249249 0x249249 0x249249 0x249249 0x249249 0x249249 0x249249 0x0 0x0 0x0 0x0 0x0 0x0 0x0 0x0>;
			nvidia,emc-trim-pmacro-regs-per-ch = <0x28282828 0x28282828 0x28282828 0x28282828 0x11111111 0x11111111 0x11111111 0x11111111 0x0 0x0 0x0 0x0 0x0 0x0 0x0 0x0 0x120013 0x110013 0x140010 0x100010 0x0 0x0 0x0 0x0 0x0 0x0 0x0 0x0 0x120013 0x110013 0x140010 0x100010 0x280028 0x280028 0x280028 0x280028 0x280028 0x280028 0x280028 0x280028 0x280028 0x280028 0x280028 0x280028 0x280028 0x280028 0x280028 0x280028 0x0 0x0 0x0 0x0 0x0 0x0 0x0 0x0 0x0 0x0 0x0 0x0 0x0 0x0 0x0 0x0 0x0 0x0 0x0 0x0 0x0 0x0 0x0 0x0 0x0 0x0 0x0 0x0 0x0 0x0 0x0 0x0 0x0 0x0 0x0 0x0 0x0 0x0 0x0 0x0 0x0 0x0 0x0 0x0 0x0 0x0 0x0 0x0 0x0 0x0 0x0 0x0 0x0 0x0 0x0 0x0 0x0 0x0 0x0 0x0 0x0 0x0 0x0 0x0 0x0 0x0 0x0 0x0 0x0 0x0 0x0 0x0 0x0 0x0 0x0 0x0 0x0 0x0 0x0 0x0 0x0 0x0 0x0 0x0 0x0 0x0 0x0 0x0 0x0 0x0 0x0 0x0 0x0 0x0 0x0 0x0 0x0 0x0 0x0 0x0 0x0 0x0 0x0 0x0 0x0 0x0 0x0 0x0 0x0 0x0 0x0 0x0 0x0 0x0 0x0 0x0 0x0 0x0 0x0 0x0 0x0 0x0 0x0 0x0 0x0 0x0 0x0 0x0 0x0 0x0 0x0 0x0 0x0 0x0 0x0 0x0 0x0 0x0 0x0 0x0 0x0 0x0 0x0 0x0 0x0 0x0 0x0 0x0 0x0 0x0 0x0 0x0 0x0 0x0 0x0 0x0 0x0 0x0 0x0 0x0 0x0 0x0 0x0 0x0 0x0 0x0 0x0 0x0 0x0 0x0 0x0 0x0 0x0 0x0 0x0 0x0 0x0 0x0 0x0 0x0 0x0 0x0 0x0 0x0 0x0 0x0 0x0 0x0 0x0 0x0 0x0 0x0 0x0 0x0 0x0 0x0 0x0 0x0 0x0 0x0 0x0 0x0 0x0 0x0 0x0 0x0 0x0 0x0>;
			nvidia,emc-vref-regs = <0x0 0x0 0x0 0x0 0x0 0x0 0x0 0x0>;
			nvidia,emc-dram-timing-regs = <0x13 0x104 0xb4 0x18 0x6>;
			nvidia,emc-zqcal-param-regs = <0x0 0x0 0x0 0x0 0xf4240 0x960>;
			nvidia,emc-opt-regs = <0x0 0x0 0x0 0x1 0x0 0x0 0x1 0x0>;
			nvidia,emc-training-mod-regs = <0x0 0x0 0x0 0x0 0x0 0x0 0x0 0x0 0x0 0x0 0x0 0x0 0x0 0x0 0x0 0x0 0x0 0x0 0x0 0x0 0x0 0x0 0x0 0x0 0x0 0x0 0x0 0x0 0x0 0x0 0x0 0x0 0x0 0x0 0x0 0x0 0x0 0x0 0x0 0x0>;
			nvidia,emc-save-restore-mod-regs = <0x0 0x0 0x0 0x0 0x0 0x0 0x0 0x0 0x0 0x0 0x0 0x0 0x0 0x0 0x0 0x0>;
			nvidia,emc-burst-mc-regs = <0x8000001 0x800000e8 0x800000d8 0xa1020 0x80001028 0x1 0x1 0x3 0x1 0x2 0x1 0x2 0x4 0x2 0x1 0x4 0x8 0x5 0x4 0x2020001 0x30201 0x71c30504 0x70000f0f 0x0 0x3f0000 0x3f0000 0x20400000 0x40004 0x80001a 0x80001a 0x80001a 0x80001a 0x80001a 0x80001a 0x80001a 0x80001a 0x80001a>;
			nvidia,emc-la-scale-regs = <0x1e 0x24c 0xff00f6 0xff00f6 0xff00bd 0xff00ff 0xff00ff 0xff00ff 0xff00f1 0xff0004 0xbd 0xff00fb 0xff00fb 0xff00b1 0xff0073 0xff00fb 0xff 0xfa 0xff00ff 0xff 0xce 0xce 0xff00ff 0xff000a 0xff00bd 0xff000a 0xff00bc 0xff00f8 0xff000a 0xff00bd 0xff00f7 0xff0050 0xff0024 0xff00f5 0xff00fb 0xff000a 0xff00bd 0xff00f9 0xff00bd 0xff00f8>;
			nvidia,emc-fdr-sequence-regs = <0x14 0x18 0x1f4 0x1 0x0 0x0 0x1c>;
			nvidia,emc-debug-regs = <0x21 0x0 0x0 0x0 0x0 0x0 0x0>;
			nvidia,emc-mempll-spread-spectrum-regs = <0xc0000000 0x40082fb 0x10400 0xc0000000 0x40082fb 0x10400 0xc0000000 0x40082fb 0x10400 0xc0000000 0x40082fb 0x10400>;
			nvidia,min-mrs-wait = <0x10>;
			nvidia,bg-ilvl-ctrl = <0x0>;
			nvidia,emc-mrw = <0x8010004>;
			nvidia,emc-mrw2 = <0x8020000>;
			nvidia,emc-mrw3 = <0x80d0000>;
			nvidia,emc-mrw4 = <0xc0000000>;
			nvidia,emc-mrw9-0 = <0xc0e6060>;
			nvidia,emc-mrw9-2 = <0xc0e6060>;
			nvidia,emc-mrs = <0x0>;
			nvidia,emc-emrs = <0x0>;
			nvidia,emc-emrs2 = <0x0>;
			nvidia,emc-auto-cal-config = <0xa01a51d8>;
			nvidia,emc-auto-cal-config2 = <0x5500000>;
			nvidia,emc-auto-cal-config3-0 = <0x880000>;
			nvidia,emc-auto-cal-config3-2 = <0x880000>;
			nvidia,emc-auto-cal-config4-0 = <0x880000>;
			nvidia,emc-auto-cal-config4-2 = <0x880000>;
			nvidia,emc-auto-cal-config5-0 = <0x880000>;
			nvidia,emc-auto-cal-config5-2 = <0x880000>;
			nvidia,emc-auto-cal-config6-0 = <0x880000>;
			nvidia,emc-auto-cal-config6-2 = <0x880000>;
			nvidia,emc-auto-cal-config7-0 = <0x880000>;
			nvidia,emc-auto-cal-config7-2 = <0x880000>;
			nvidia,emc-auto-cal-config8-0 = <0x880000>;
			nvidia,emc-auto-cal-config8-2 = <0x880000>;
			nvidia,emc-cfg-2 = <0x110825>;
			nvidia,emc-sel-dpd-ctrl = <0x40008>;
			nvidia,emc-fdpd-ctrl-cmd-no-ramp = <0x1>;
			nvidia,dll-clk-src = <0x40008002>;
			nvidia,clk-out-enb-x-0-clk-enb-emc-dll = <0x1>;
			nvidia,emc-clock-latency-change = <0xd5c>;
		};

		emc-table-derated@1600000 {
			compatible = "nvidia,tegra18-emc-table-derated";
			nvidia,revision = <0xa>;
			nvidia,dvfs-version = "09_1600000_NoCfgVersion_V1.3.8_V4.9";
			clock-frequency = <0x186a00>;
			nvidia,emc-min-mv = <0x35c>;
			nvidia,gk20a-min-mv = <0x44c>;
			nvidia,source = "pllm_ud";
			nvidia,src-sel-reg = <0x80008000>;
			nvidia,mem-pll-ssc-control = <0x1>;
			nvidia,needs-training = <0x2f0>;
			nvidia,training_pattern = <0x0>;
			nvidia,trained = <0x0>;
			nvidia,periodic_training = <0x1>;
			nvidia,trained_dram_clktree_c0d0u0 = <0x0>;
			nvidia,trained_dram_clktree_c0d0u1 = <0x0>;
			nvidia,trained_dram_clktree_c0d1u0 = <0x0>;
			nvidia,trained_dram_clktree_c0d1u1 = <0x0>;
			nvidia,trained_dram_clktree_c1d0u0 = <0x0>;
			nvidia,trained_dram_clktree_c1d0u1 = <0x0>;
			nvidia,trained_dram_clktree_c1d1u0 = <0x0>;
			nvidia,trained_dram_clktree_c1d1u1 = <0x0>;
			nvidia,trained_dram_clktree_c2d0u0 = <0x0>;
			nvidia,trained_dram_clktree_c2d0u1 = <0x0>;
			nvidia,trained_dram_clktree_c2d1u0 = <0x0>;
			nvidia,trained_dram_clktree_c2d1u1 = <0x0>;
			nvidia,trained_dram_clktree_c3d0u0 = <0x0>;
			nvidia,trained_dram_clktree_c3d0u1 = <0x0>;
			nvidia,trained_dram_clktree_c3d1u0 = <0x0>;
			nvidia,trained_dram_clktree_c3d1u1 = <0x0>;
			nvidia,current_dram_clktree_c0d0u0 = <0x0>;
			nvidia,current_dram_clktree_c0d0u1 = <0x0>;
			nvidia,current_dram_clktree_c0d1u0 = <0x0>;
			nvidia,current_dram_clktree_c0d1u1 = <0x0>;
			nvidia,current_dram_clktree_c1d0u0 = <0x0>;
			nvidia,current_dram_clktree_c1d0u1 = <0x0>;
			nvidia,current_dram_clktree_c1d1u0 = <0x0>;
			nvidia,current_dram_clktree_c1d1u1 = <0x0>;
			nvidia,current_dram_clktree_c2d0u0 = <0x0>;
			nvidia,current_dram_clktree_c2d0u1 = <0x0>;
			nvidia,current_dram_clktree_c2d1u0 = <0x0>;
			nvidia,current_dram_clktree_c2d1u1 = <0x0>;
			nvidia,current_dram_clktree_c3d0u0 = <0x0>;
			nvidia,current_dram_clktree_c3d0u1 = <0x0>;
			nvidia,current_dram_clktree_c3d1u0 = <0x0>;
			nvidia,current_dram_clktree_c3d1u1 = <0x0>;
			nvidia,emc_channel_enable = <0xf>;
			nvidia,run_clocks = <0x40>;
			nvidia,tree_margin = <0x1>;
			nvidia,burst-regs-num = <0x92>;
			nvidia,burst-regs-per-ch-num = <0x38>;
			nvidia,burst-pmacro-regs-per-ch-num = <0xa2>;
			nvidia,trim-regs-per-ch-num = <0x14>;
			nvidia,trim-pmacro-regs-per-ch-num = <0x100>;
			nvidia,vref-regs-num = <0x8>;
			nvidia,dram-timing-regs-num = <0x5>;
			nvidia,training-mod-regs-num = <0x28>;
			nvidia,burst-mc-regs-num = <0x25>;
			nvidia,la-scale-regs-num = <0x28>;
			nvidia,emc-ptfv-list = <0x0 0x0 0x0 0x0 0x0 0x0 0x0 0x0 0x0 0x0 0x0 0x0 0x0 0x0 0x0 0x0 0xa 0xa 0xa 0x1>;
			nvidia,emc-registers = <0x66 0x120 0x90 0x0 0x0 0x47 0x20 0x2a 0x21 0xc 0x2d 0x0 0x4 0x3a 0x23 0x3e 0x41 0x0 0x20 0x20 0x20 0x13 0x17 0x16 0x6 0xe 0xc 0xa 0xe 0x8 0xd 0x24 0x9 0x1000001c 0x10000002 0x14 0x803f1f1 0x1d 0x1 0x80000000 0x6000c 0x34 0x3a 0x3c 0x38 0x3a 0x5e9 0x0 0x17a 0x10 0x10 0x3 0x17 0x3 0x38 0xe 0x2 0x31 0x12c 0x12c 0xd 0x18 0xc 0x40 0x25 0x4 0x14 0x4803f1f1 0x1860 0x0 0x9980a00d 0x3bff 0x0 0xc00001bb 0x8000 0x64 0x80b6666 0x0 0x0 0x0 0x0 0x409 0x8020221f 0x220f40f 0x12 0x64000 0x310640 0x640002f 0x1900017 0xc1e00309 0x1f13612f 0x200014 0x101fdd 0x331010 0x80d 0x550 0xf3200000 0xce6 0xce6 0x2c 0x20000 0x33 0x0 0x211 0x3000 0x2000000 0x2000101 0x0 0xd0909 0x156210 0x140404 0x1fff 0x0 0x80 0x0 0x30 0x40 0x20 0xefff2010 0x0 0x0 0xdcdcdcdc 0xa0a0a0a 0xa0a0a0a 0xa0a0a0a 0x1186190 0x0 0x0 0x3a 0x2c 0x3c 0x8161414 0x34 0x6000c 0x9080 0x7070404 0x40320 0x513801f 0x1f101100 0x14 0x1110fc00 0xf085300 0x1114fc00 0x7004300 0x55553c5a 0x48161414>;
			nvidia,emc-burst-regs-per-ch = <0xfff0000 0xfff0000 0xfff0000 0xfff0000 0xfff0000 0xfff0000 0xfff0000 0xfff0000 0x0 0x0 0x0 0x0 0x880c4848 0x880c4848 0x880c4848 0x880c4848 0x480c4848 0x480c4848 0x480c4848 0x480c4848 0x8c0e4848 0x8c0e4848 0x8c0e4848 0x8c0e4848 0x4c0e4848 0x4c0e4848 0x4c0e4848 0x4c0e4848 0x0 0x0 0x0 0x0 0x0 0x0 0x0 0x0 0x1b 0x1b 0x1b 0x1b 0x1b 0x1b 0x1b 0x1b 0x103200 0x103200 0x103200 0x103200 0x102c00 0x102c00 0x102c00 0x102c00 0x102900 0x102900 0x102900 0x102900>;
			nvidia,emc-pmacro-regs-per-ch = <0xb000b 0xb000b 0xb000b 0xa000a 0x90009 0xa000a 0xc000c 0x90009 0xb 0xb 0x0 0x0 0x0 0x0 0x0 0x0 0x0 0x0 0x0 0x0 0x0 0x0 0x0 0x0 0x0 0x0 0x0 0x0 0x0 0x0 0x0 0x0 0x0 0x0 0x0 0x0 0x0 0x0 0x0 0x0 0x0 0x0 0x0 0x0 0x0 0x0 0x0 0x0 0x0 0x0 0x0 0x0 0x0 0x0 0x0 0x0 0x0 0x0 0x0 0x0 0x0 0x0 0x0 0x0 0x0 0x0 0x0 0x0 0x0 0x0 0x0 0x0 0x0 0x0 0x0 0x0 0x0 0x0 0x0 0x0 0x0 0x0 0x0 0x0 0x0 0x0 0x0 0x0 0x0 0x0 0x0 0x0 0x0 0x0 0x0 0x0 0x0 0x0 0x0 0x0 0x0 0x0 0x0 0x0 0x0 0x0 0x5 0x5 0x7 0x2000a 0x5 0x8 0x2 0x5 0x30005 0x3 0x80005 0x30000 0x5 0x5 0x7 0x2000a 0x5 0x8 0x2 0x5 0x30005 0x3 0x80005 0x30000 0x0 0x0 0x0 0x0 0x0 0x0 0x0 0x0 0x0 0x0 0x0 0x8000000 0x8000000 0x8000000 0x0 0x0 0x8000800 0x800 0x0 0x0 0x0 0x0 0x0 0x0 0x0 0x0 0x0 0x0 0x0 0x0 0x0 0x0>;
			nvidia,emc-shadow-regs-ca-train = <0x66 0x120 0x90 0x0 0x0 0x47 0x20 0x2a 0x21 0xc 0x2d 0x0 0x4 0x3a 0x23 0x3e 0x41 0x0 0x20 0x20 0x20 0x13 0x17 0x16 0x6 0xe 0xc 0xa 0xe 0x8 0xd 0x24 0x9 0x1000001c 0x10000002 0x14 0x803f1f1 0x1d 0x1 0x80000000 0x6000c 0x34 0x3a 0x3c 0x38 0x3a 0x5e9 0x0 0x17a 0x10 0x10 0x3 0x17 0x3 0x38 0xe 0x2 0x31 0x12c 0x12c 0xd 0x18 0xc 0x40 0x25 0x4 0x14 0x4803f1f1 0x1860 0x0 0x9980a00d 0x3bff 0x0 0xc00001bb 0x8000 0x64 0x80b6666 0x0 0x0 0x0 0x0 0x409 0x8020221f 0x220f40f 0x12 0x64000 0x310640 0x640002f 0x1900017 0xc1e00309 0x1f13612f 0x200014 0x101fdd 0x331010 0x80d 0x550 0xf3200000 0xce6 0xce6 0x2c 0x20000 0x8033 0x0 0x200 0x3000 0x2000000 0x2000101 0x0 0xd0909 0x156210 0x140404 0x1fff 0x0 0x80 0x0 0x30 0x40 0x20 0xefff2010 0x0 0x0 0xdcdcdcdc 0xa0a0a0a 0xa0a0a0a 0xa0a0a0a 0x1186190 0x1 0x1f 0x40 0x2c 0x42 0x8161414 0x34 0x6000c 0x19080 0x7070404 0x40320 0x513801f 0x1f101100 0x14 0x1110fc00 0xf085300 0x1114fc00 0x7004300 0x55553c5a 0x48161414>;
			nvidia,emc-shadow-regs-rdwr-train = <0x66 0x120 0x90 0x0 0x0 0x47 0x20 0x2a 0x22 0xc 0x2d 0x0 0x4 0x3a 0x23 0x3e 0x41 0x0 0x20 0x20 0x20 0x13 0x17 0x16 0x6 0xe 0xc 0xa 0xe 0x8 0xd 0x24 0x9 0x1000001c 0x10000002 0x14 0x803f1f1 0x1d 0x1 0x80000000 0x6000c 0x34 0x3a 0x3c 0x38 0x3a 0x5e9 0x0 0x17a 0x10 0x10 0x3 0x17 0x3 0x38 0xe 0x2 0x31 0x12c 0x12c 0xd 0x18 0xc 0x40 0x25 0x4 0x14 0x4803f1f1 0x1860 0x0 0x9980a00d 0x3bff 0x0 0xc00001bb 0x8000 0x64 0x80b6666 0x0 0x0 0x0 0x0 0x409 0x8020221f 0x220f40f 0x12 0x64000 0x310640 0x640002f 0x1900017 0xc1e00309 0x1f13612f 0x200014 0x101fdd 0x331010 0x80d 0x550 0xf3200000 0xce6 0xce6 0x2c 0x20000 0x33 0x0 0x211 0x3000 0x2000000 0x2000101 0x0 0xd0909 0x156210 0x140404 0x1fff 0x0 0x80 0x0 0x30 0x40 0x20 0xefff2010 0x0 0x0 0xdcdcdcdc 0xa0a0a0a 0xa0a0a0a 0xa0a0a0a 0x1186190 0x1 0x0 0x3a 0x2c 0x3c 0x8161414 0x34 0x6000c 0xb080 0x7070404 0x40320 0x513801f 0x1f101100 0x14 0x1110fc00 0xf085300 0x1114fc00 0x7004300 0x55553c5a 0x48161414>;
			nvidia,emc-trim-regs-per-ch = <0x0 0x0 0x0 0x0 0x0 0x0 0x0 0x0 0x0 0x0 0x0 0x0 0x0 0x0 0x0 0x0 0x0 0x0 0x0 0x0>;
			nvidia,emc-trim-pmacro-regs-per-ch = <0x11111111 0x11111111 0x11111111 0x11111111 0x11111111 0x11111111 0x11111111 0x11111111 0x220024 0x230026 0x210027 0x240029 0x230029 0x210028 0x230027 0x220027 0xb000b 0xa000b 0xc0009 0x9000a 0x220024 0x230026 0x210027 0x240029 0x230029 0x210028 0x230027 0x220027 0xb000b 0xa000b 0xc0009 0x9000a 0x200020 0x200020 0x200020 0x200020 0x200020 0x200020 0x200020 0x200020 0x200020 0x200020 0x200020 0x200020 0x200020 0x200020 0x200020 0x200020 0x0 0x0 0x0 0x0 0x0 0x0 0x0 0x0 0x0 0x0 0x0 0x0 0x0 0x0 0x0 0x0 0x0 0x0 0x0 0x0 0x0 0x0 0x0 0x0 0x0 0x0 0x0 0x0 0x0 0x0 0x0 0x0 0x0 0x0 0x0 0x0 0x0 0x0 0x0 0x0 0x0 0x0 0x0 0x0 0x0 0x0 0x0 0x0 0x0 0x0 0x0 0x0 0x0 0x0 0x0 0x0 0x0 0x0 0x0 0x0 0x0 0x0 0x0 0x0 0x0 0x0 0x0 0x0 0x0 0x0 0x0 0x0 0x0 0x0 0x0 0x0 0x0 0x0 0x0 0x0 0x0 0x0 0x0 0x0 0x0 0x0 0x0 0x0 0x0 0x0 0x0 0x0 0x0 0x0 0x0 0x0 0x0 0x0 0x0 0x0 0x0 0x0 0x0 0x0 0x0 0x0 0x0 0x0 0x0 0x0 0x0 0x0 0x0 0x0 0x0 0x0 0x0 0x0 0x0 0x0 0x0 0x0 0x0 0x0 0x0 0x0 0x0 0x0 0x0 0x0 0x0 0x0 0x0 0x0 0x0 0x0 0x0 0x0 0x0 0x0 0x0 0x0 0x0 0x0 0x0 0x0 0x0 0x0 0x0 0x0 0x0 0x0 0x0 0x0 0x0 0x0 0x0 0x0 0x0 0x0 0x0 0x0 0x0 0x0 0x0 0x0 0x0 0x0 0x0 0x0 0x0 0x0 0x0 0x0 0x0 0x0 0x0 0x0 0x0 0x0 0x0 0x0 0x0 0x0 0x0 0x0 0x0 0x0 0x0 0x0 0x0 0x0 0x0 0x0 0x0 0x0 0x0 0x0 0x0 0x0 0x0 0x0 0x0 0x0 0x0 0x0 0x0 0x0>;
			nvidia,emc-vref-regs = <0x0 0x0 0x0 0x0 0x0 0x0 0x0 0x0>;
			nvidia,emc-dram-timing-regs = <0x13 0x104 0xb4 0x7 0x20>;
			nvidia,emc-zqcal-param-regs = <0x0 0x0 0x0 0x0 0xf4240 0x960>;
			nvidia,emc-opt-regs = <0x0 0x0 0x0 0x1 0x0 0x0 0x1 0x0>;
			nvidia,emc-training-mod-regs = <0x0 0x0 0x0 0x0 0x0 0x0 0x0 0x0 0x0 0x0 0x0 0x0 0x0 0x0 0x0 0x0 0x0 0x0 0x0 0x0 0x0 0x0 0x0 0x0 0x0 0x0 0x0 0x0 0x0 0x0 0x0 0x0 0x0 0x0 0x0 0x0 0x0 0x0 0x0 0x0>;
			nvidia,emc-save-restore-mod-regs = <0x0 0x0 0x0 0x0 0x0 0x0 0x0 0x0 0x0 0x0 0x0 0x0 0x0 0x0 0x0 0x0>;
			nvidia,emc-burst-mc-regs = <0xc 0x80000100 0x800000f0 0xa1020 0x80001028 0x6 0x7 0x19 0x10 0xf 0x4 0x3 0xe 0x7 0x7 0xc 0x8 0xa 0x23 0x5060303 0xe090c 0x718c241a 0x70000f0f 0x0 0x3f0000 0x3f0000 0x20400000 0x40004 0x80001a 0x80001a 0x80001a 0x80001a 0x80001a 0x80001a 0x80001a 0x80001a 0x80001a>;
			nvidia,emc-la-scale-regs = <0xe7 0x1203 0x80007b 0x80007b 0x8000bd 0x8000ff 0x8000ff 0x8000ff 0x8000f1 0x800004 0xbd 0x800020 0x800020 0x800023 0x800023 0x800020 0x80 0x20 0x800080 0x80 0x64e 0x64e 0x800021 0x80000a 0x8000bd 0x80000a 0x8000bc 0x80007c 0x80000a 0x8000bd 0x800020 0x800050 0x800024 0x80001f 0x800039 0x80000a 0x8000bd 0x800020 0x8000bd 0x800020>;
			nvidia,emc-fdr-sequence-regs = <0x14 0x18 0x1f4 0x1 0x1b 0x19 0x0>;
			nvidia,emc-debug-regs = <0x21 0x0 0x0 0x0 0x0 0x0 0x0>;
			nvidia,emc-mempll-spread-spectrum-regs = <0xc0000000 0xfaabf2ab 0x7faab 0xc0000000 0xfaabf2ab 0x7faab 0xc0000000 0xfaabf2ab 0x7faab 0xc0000000 0xfaabf2ab 0x7faab>;
			nvidia,min-mrs-wait = <0x2f>;
			nvidia,bg-ilvl-ctrl = <0x0>;
			nvidia,emc-mrw = <0x8010054>;
			nvidia,emc-mrw2 = <0x802002d>;
			nvidia,emc-mrw3 = <0x80d0000>;
			nvidia,emc-mrw4 = <0xc0000000>;
			nvidia,emc-mrw9-0 = <0xc0e4848>;
			nvidia,emc-mrw9-2 = <0xc0e4848>;
			nvidia,emc-mrs = <0x0>;
			nvidia,emc-emrs = <0x0>;
			nvidia,emc-emrs2 = <0x0>;
			nvidia,emc-auto-cal-config = <0xa01a51d8>;
			nvidia,emc-auto-cal-config2 = <0x5500000>;
			nvidia,emc-auto-cal-config3-0 = <0x880000>;
			nvidia,emc-auto-cal-config3-2 = <0x880000>;
			nvidia,emc-auto-cal-config4-0 = <0x880000>;
			nvidia,emc-auto-cal-config4-2 = <0x880000>;
			nvidia,emc-auto-cal-config5-0 = <0x880000>;
			nvidia,emc-auto-cal-config5-2 = <0x880000>;
			nvidia,emc-auto-cal-config6-0 = <0x880000>;
			nvidia,emc-auto-cal-config6-2 = <0x880000>;
			nvidia,emc-auto-cal-config7-0 = <0x880000>;
			nvidia,emc-auto-cal-config7-2 = <0x880000>;
			nvidia,emc-auto-cal-config8-0 = <0x880000>;
			nvidia,emc-auto-cal-config8-2 = <0x880000>;
			nvidia,emc-cfg-2 = <0x110835>;
			nvidia,emc-sel-dpd-ctrl = <0x40000>;
			nvidia,emc-fdpd-ctrl-cmd-no-ramp = <0x0>;
			nvidia,dll-clk-src = <0x80008000>;
			nvidia,clk-out-enb-x-0-clk-enb-emc-dll = <0x0>;
			nvidia,emc-clock-latency-change = <0x49c>;
		};
	};

	external-memory-1 {
		compatible = "nvidia,tegra18-emc";
		reg = <0x0 0x2c10000 0x0 0x10000>;
		#address-cells = <0x1>;
		#size-cells = <0x0>;
		linux,phandle = <0x9>;
		phandle = <0x9>;

		emc-table@204000 {
			compatible = "nvidia,tegra18-emc-table";
			nvidia,revision = <0xa>;
			nvidia,dvfs-version = "07_204000_NoCfgVersion_V1.3.4_V4.9";
			clock-frequency = <0x31ce0>;
			nvidia,emc-min-mv = <0x44c>;
			nvidia,gk20a-min-mv = <0x44c>;
			nvidia,source = "pllp_out0";
			nvidia,src-sel-reg = <0x40008002>;
			nvidia,mem-pll-ssc-control = <0x1>;
			nvidia,needs-training = <0x0>;
			nvidia,training_pattern = <0x0>;
			nvidia,trained = <0x0>;
			nvidia,periodic_training = <0x0>;
			nvidia,trained_dram_clktree_c0d0u0 = <0x0>;
			nvidia,trained_dram_clktree_c0d0u1 = <0x0>;
			nvidia,trained_dram_clktree_c0d1u0 = <0x0>;
			nvidia,trained_dram_clktree_c0d1u1 = <0x0>;
			nvidia,trained_dram_clktree_c1d0u0 = <0x0>;
			nvidia,trained_dram_clktree_c1d0u1 = <0x0>;
			nvidia,trained_dram_clktree_c1d1u0 = <0x0>;
			nvidia,trained_dram_clktree_c1d1u1 = <0x0>;
			nvidia,trained_dram_clktree_c2d0u0 = <0x0>;
			nvidia,trained_dram_clktree_c2d0u1 = <0x0>;
			nvidia,trained_dram_clktree_c2d1u0 = <0x0>;
			nvidia,trained_dram_clktree_c2d1u1 = <0x0>;
			nvidia,trained_dram_clktree_c3d0u0 = <0x0>;
			nvidia,trained_dram_clktree_c3d0u1 = <0x0>;
			nvidia,trained_dram_clktree_c3d1u0 = <0x0>;
			nvidia,trained_dram_clktree_c3d1u1 = <0x0>;
			nvidia,current_dram_clktree_c0d0u0 = <0x0>;
			nvidia,current_dram_clktree_c0d0u1 = <0x0>;
			nvidia,current_dram_clktree_c0d1u0 = <0x0>;
			nvidia,current_dram_clktree_c0d1u1 = <0x0>;
			nvidia,current_dram_clktree_c1d0u0 = <0x0>;
			nvidia,current_dram_clktree_c1d0u1 = <0x0>;
			nvidia,current_dram_clktree_c1d1u0 = <0x0>;
			nvidia,current_dram_clktree_c1d1u1 = <0x0>;
			nvidia,current_dram_clktree_c2d0u0 = <0x0>;
			nvidia,current_dram_clktree_c2d0u1 = <0x0>;
			nvidia,current_dram_clktree_c2d1u0 = <0x0>;
			nvidia,current_dram_clktree_c2d1u1 = <0x0>;
			nvidia,current_dram_clktree_c3d0u0 = <0x0>;
			nvidia,current_dram_clktree_c3d0u1 = <0x0>;
			nvidia,current_dram_clktree_c3d1u0 = <0x0>;
			nvidia,current_dram_clktree_c3d1u1 = <0x0>;
			nvidia,emc_channel_enable = <0xf>;
			nvidia,run_clocks = <0xd>;
			nvidia,tree_margin = <0x1>;
			nvidia,burst-regs-num = <0x92>;
			nvidia,burst-regs-per-ch-num = <0x38>;
			nvidia,burst-pmacro-regs-per-ch-num = <0xa2>;
			nvidia,trim-regs-per-ch-num = <0x14>;
			nvidia,trim-pmacro-regs-per-ch-num = <0x100>;
			nvidia,vref-regs-num = <0x8>;
			nvidia,dram-timing-regs-num = <0x5>;
			nvidia,training-mod-regs-num = <0x28>;
			nvidia,burst-mc-regs-num = <0x25>;
			nvidia,la-scale-regs-num = <0x28>;
			nvidia,emc-ptfv-list = <0x0 0x0 0x0 0x0 0x0 0x0 0x0 0x0 0x0 0x0 0x0 0x0 0x0 0x0 0x0 0x0 0xa 0xa 0xa 0x1>;
			nvidia,emc-registers = <0xd 0x25 0x13 0x0 0x0 0x9 0x4 0xb 0xd 0x8 0xb 0x0 0x4 0x17 0x15 0x17 0x1b 0x0 0x20 0x6 0x6 0x6 0x3 0x0 0x6 0x4 0x2 0x0 0x4 0x8 0xd 0x5 0x6 0x0 0x0 0x2 0x8033131 0xd 0x1 0x80000000 0x10000 0x12 0x18 0x1a 0x16 0x18 0x304 0x0 0xc1 0x8 0x8 0x3 0xa 0x3 0x14 0x5 0x2 0xd 0x27 0x27 0x5 0x5 0x4 0x9 0x5 0x4 0x9 0x48033131 0x31c 0x0 0x9180a00d 0x3a3f 0x0 0x2c00a0 0x8000 0x64 0x80b0000 0x0 0x0 0x0 0x0 0x409 0x8020221f 0x220f40f 0x12 0x64000 0x900cc 0xcc0010 0x33000a 0xc1e00302 0x1f13412f 0x110014 0x101fdd 0x331010 0x804 0x550 0xf3200000 0x80000713 0x713 0xa 0x20000 0x50037 0x0 0x10 0x3000 0xa000000 0x2000111 0x8 0xd0909 0x156210 0x140404 0x1600 0x0 0x0 0x0 0x30 0x40 0x20 0xefffefff 0xc0c0c0c0 0xc0c0c0c0 0xdcdcdcdc 0xa0a0a0a 0xa0a0a0a 0xa0a0a0a 0x1186033 0x0 0x0 0x18 0xa 0x1a 0x8161414 0x12 0x10000 0x9080 0x7070404 0x40065 0x513801f 0x1f101100 0x14 0x1110fc00 0xf081300 0x1114fc00 0x7000300 0x55553c5a 0x48161414>;
			nvidia,emc-burst-regs-per-ch = <0xfff0000 0xfff0000 0xfff0000 0xfff0000 0xfff0000 0xfff0000 0xfff0000 0xfff0000 0x0 0x0 0x0 0x0 0x880c7272 0x880c7272 0x880c7272 0x880c7272 0x480c7272 0x480c7272 0x480c7272 0x480c7272 0x8c0e6060 0x8c0e6060 0x8c0e6060 0x8c0e6060 0x4c0e6060 0x4c0e6060 0x4c0e6060 0x4c0e6060 0x0 0x0 0x0 0x0 0x0 0x0 0x0 0x0 0x1b 0x1b 0x1b 0x1b 0x1b 0x1b 0x1b 0x1b 0x107240 0x107240 0x107240 0x107240 0x105835 0x105835 0x105835 0x105835 0x107252 0x107252 0x107252 0x107252>;
			nvidia,emc-pmacro-regs-per-ch = <0x130013 0x130013 0x120012 0x110011 0x100010 0x100010 0x140014 0x100010 0x13 0x13 0x0 0x0 0x0 0x0 0x0 0x0 0x0 0x0 0x0 0x0 0x0 0x0 0x0 0x0 0x0 0x0 0x0 0x0 0x0 0x0 0x0 0x0 0x0 0x0 0x0 0x0 0x0 0x0 0x0 0x0 0x0 0x0 0x0 0x0 0x0 0x0 0x0 0x0 0x0 0x0 0x0 0x0 0x0 0x0 0x0 0x0 0x0 0x0 0x0 0x0 0x0 0x0 0x0 0x0 0x0 0x0 0x0 0x0 0x0 0x0 0x0 0x0 0x0 0x0 0x0 0x0 0x0 0x0 0x0 0x0 0x0 0x0 0x0 0x0 0x0 0x0 0x0 0x0 0x0 0x0 0x0 0x0 0x0 0x0 0x0 0x0 0x0 0x0 0x0 0x0 0x0 0x0 0x0 0x0 0x0 0x0 0x460041 0x470044 0x440043 0x460042 0x470048 0x450041 0x48004b 0x460047 0x50009 0x5 0xd0008 0x50000 0x460041 0x470044 0x440043 0x460042 0x470048 0x450041 0x48004b 0x460047 0x50009 0x5 0xd0008 0x50000 0x0 0x0 0x0 0x0 0x0 0x0 0x0 0x0 0x0 0x0 0x0 0x8000000 0x8000000 0x8000000 0x0 0x0 0x8000800 0x800 0x0 0x0 0x0 0x0 0x0 0x0 0x0 0x0 0x0 0x0 0x0 0x0 0x0 0x0>;
			nvidia,emc-shadow-regs-ca-train = <0xd 0x25 0x13 0x0 0x0 0x9 0x4 0xb 0xd 0x8 0xb 0x0 0x4 0x17 0x15 0x17 0x1b 0x0 0x20 0x6 0x6 0x6 0x3 0x0 0x6 0x4 0x2 0x0 0x4 0x8 0xd 0x5 0x6 0x0 0x0 0x2 0x8033131 0xd 0x1 0x80000000 0x10000 0x12 0x18 0x1a 0x16 0x18 0x304 0x0 0xc1 0x8 0x8 0x3 0xa 0x3 0x14 0x5 0x2 0xd 0x27 0x27 0x5 0x5 0x4 0x9 0x5 0x4 0x9 0x48033131 0x31c 0x0 0x9980a00d 0x3a3f 0x0 0x2c00a0 0x8000 0x64 0x80b0000 0x0 0x0 0x0 0x0 0x409 0x8020221f 0x220f40f 0x12 0x64000 0x900cc 0xcc0010 0x33000a 0xc1e00302 0x1f13412f 0x110014 0x101fdd 0x331010 0x804 0x550 0xf3200000 0x80000713 0x713 0xa 0x20000 0x5058033 0x5050000 0x0 0x3000 0xa000000 0x2000111 0x8 0xd0909 0x156210 0x140404 0x1600 0x0 0x0 0x0 0x30 0x40 0x20 0xefffefff 0xc0c0c0c0 0xc0c0c0c0 0xdcdcdcdc 0xa0a0a0a 0xa0a0a0a 0xa0a0a0a 0x1186033 0x1 0x1f 0x1c 0x8 0x1e 0x8161414 0x10 0x10000 0x19080 0x7070404 0x40065 0x513801f 0x1f101100 0x14 0x1110fc00 0xf081300 0x1114fc00 0x7000300 0x55553c5a 0x48161414>;
			nvidia,emc-shadow-regs-rdwr-train = <0xd 0x25 0x13 0x0 0x0 0x9 0x4 0xe 0xe 0x8 0xb 0x0 0x4 0x17 0x15 0x17 0x1b 0x0 0x20 0x6 0x6 0x6 0x13 0x13 0x6 0x4 0x2 0x0 0x4 0x8 0xd 0x5 0x6 0x30000000 0x30000002 0x2 0x8033131 0xd 0x1 0x80000000 0x40000 0x12 0x18 0x1a 0x16 0x18 0x304 0x0 0xc1 0x8 0x8 0x3 0xa 0x3 0x14 0x5 0x2 0xd 0x27 0x27 0x5 0x5 0x4 0x9 0x5 0x4 0x9 0x48033131 0x31c 0x0 0x9180a00d 0x3a3f 0x0 0x2c00a0 0x8000 0x64 0x80b0000 0x0 0x0 0x0 0x0 0x409 0x8020221f 0x220f40f 0x12 0x64000 0x900cc 0xcc0010 0x33000a 0xc1e00302 0x1f13412f 0x110014 0x101fdd 0x331010 0x804 0x550 0xf3200000 0x80000713 0x713 0xa 0x20000 0x50037 0x0 0x10 0x3000 0xa000000 0x2000111 0x8 0xd0909 0x156210 0x140404 0x1600 0x0 0x0 0x0 0x30 0x40 0x20 0xefffefff 0xc0c0c0c0 0xc0c0c0c0 0xdcdcdcdc 0xa0a0a0a 0xa0a0a0a 0xa0a0a0a 0x1186033 0x1 0x0 0x18 0xa 0x1a 0x8161414 0x12 0x40000 0xb080 0x7070404 0x40065 0x513801f 0x1f101100 0x14 0x1110fc00 0xf081300 0x1114fc00 0x7000300 0x55553c5a 0x48161414>;
			nvidia,emc-trim-regs-per-ch = <0x0 0x0 0x0 0x0 0x249249 0x249249 0x249249 0x249249 0x249249 0x249249 0x249249 0x249249 0x0 0x0 0x0 0x0 0x0 0x0 0x0 0x0>;
			nvidia,emc-trim-pmacro-regs-per-ch = <0x28282828 0x28282828 0x28282828 0x28282828 0x11111111 0x11111111 0x11111111 0x11111111 0x0 0x0 0x0 0x0 0x0 0x0 0x0 0x0 0x120013 0x110013 0x140010 0x100010 0x0 0x0 0x0 0x0 0x0 0x0 0x0 0x0 0x120013 0x110013 0x140010 0x100010 0x280028 0x280028 0x280028 0x280028 0x280028 0x280028 0x280028 0x280028 0x280028 0x280028 0x280028 0x280028 0x280028 0x280028 0x280028 0x280028 0x0 0x0 0x0 0x0 0x0 0x0 0x0 0x0 0x0 0x0 0x0 0x0 0x0 0x0 0x0 0x0 0x0 0x0 0x0 0x0 0x0 0x0 0x0 0x0 0x0 0x0 0x0 0x0 0x0 0x0 0x0 0x0 0x0 0x0 0x0 0x0 0x0 0x0 0x0 0x0 0x0 0x0 0x0 0x0 0x0 0x0 0x0 0x0 0x0 0x0 0x0 0x0 0x0 0x0 0x0 0x0 0x0 0x0 0x0 0x0 0x0 0x0 0x0 0x0 0x0 0x0 0x0 0x0 0x0 0x0 0x0 0x0 0x0 0x0 0x0 0x0 0x0 0x0 0x0 0x0 0x0 0x0 0x0 0x0 0x0 0x0 0x0 0x0 0x0 0x0 0x0 0x0 0x0 0x0 0x0 0x0 0x0 0x0 0x0 0x0 0x0 0x0 0x0 0x0 0x0 0x0 0x0 0x0 0x0 0x0 0x0 0x0 0x0 0x0 0x0 0x0 0x0 0x0 0x0 0x0 0x0 0x0 0x0 0x0 0x0 0x0 0x0 0x0 0x0 0x0 0x0 0x0 0x0 0x0 0x0 0x0 0x0 0x0 0x0 0x0 0x0 0x0 0x0 0x0 0x0 0x0 0x0 0x0 0x0 0x0 0x0 0x0 0x0 0x0 0x0 0x0 0x0 0x0 0x0 0x0 0x0 0x0 0x0 0x0 0x0 0x0 0x0 0x0 0x0 0x0 0x0 0x0 0x0 0x0 0x0 0x0 0x0 0x0 0x0 0x0 0x0 0x0 0x0 0x0 0x0 0x0 0x0 0x0 0x0 0x0 0x0 0x0 0x0 0x0 0x0 0x0 0x0 0x0 0x0 0x0 0x0 0x0 0x0 0x0 0x0 0x0 0x0 0x0>;
			nvidia,emc-vref-regs = <0x0 0x0 0x0 0x0 0x0 0x0 0x0 0x0>;
			nvidia,emc-dram-timing-regs = <0x12 0x104 0xb4 0x18 0x6>;
			nvidia,emc-zqcal-param-regs = <0x0 0x0 0x0 0x0 0xf4240 0x960>;
			nvidia,emc-opt-regs = <0x0 0x0 0x0 0x1 0x0 0x0 0x1 0x0>;
			nvidia,emc-training-mod-regs = <0x0 0x0 0x0 0x0 0x0 0x0 0x0 0x0 0x0 0x0 0x0 0x0 0x0 0x0 0x0 0x0 0x0 0x0 0x0 0x0 0x0 0x0 0x0 0x0 0x0 0x0 0x0 0x0 0x0 0x0 0x0 0x0 0x0 0x0 0x0 0x0 0x0 0x0 0x0 0x0>;
			nvidia,emc-save-restore-mod-regs = <0x0 0x0 0x0 0x0 0x0 0x0 0x0 0x0 0x0 0x0 0x0 0x0 0x0 0x0 0x0 0x0>;
			nvidia,emc-burst-mc-regs = <0x8000001 0x800000e8 0x800000d8 0xa1020 0x80001028 0x1 0x0 0x3 0x1 0x2 0x1 0x2 0x5 0x2 0x1 0x4 0x8 0x5 0x4 0x2020001 0x30201 0x71c30504 0x70000f0f 0x0 0x3f0000 0x3f0000 0x20400000 0x40004 0x80001a 0x80001a 0x80001a 0x80001a 0x80001a 0x80001a 0x80001a 0x80001a 0x80001a>;
			nvidia,emc-la-scale-regs = <0x1e 0x24c 0xff00f6 0xff00f6 0xff00bd 0xff00ff 0xff00ff 0xff00ff 0xff00f1 0xff0004 0xbd 0xff00fb 0xff00fb 0xff00b1 0xff0073 0xff00fb 0xff 0xfa 0xff00ff 0xff 0xce 0xce 0xff00ff 0xff000a 0xff00bd 0xff000a 0xff00bc 0xff00f8 0xff000a 0xff00bd 0xff00f7 0xff0050 0xff0024 0xff00f5 0xff00fb 0xff000a 0xff00bd 0xff00f9 0xff00bd 0xff00f8>;
			nvidia,emc-fdr-sequence-regs = <0x14 0x18 0x1f4 0x1 0x0 0x0 0x1c>;
			nvidia,emc-debug-regs = <0x21 0x0 0x0 0x0 0x0 0x0 0x0>;
			nvidia,emc-mempll-spread-spectrum-regs = <0xc0000000 0xf000ef0b 0x1f000 0xc0000000 0xf000ef0b 0x1f000 0xc0000000 0xf000ef0b 0x1f000 0xc0000000 0xf000ef0b 0x1f000>;
			nvidia,min-mrs-wait = <0x10>;
			nvidia,bg-ilvl-ctrl = <0x0>;
			nvidia,emc-mrw = <0x8010004>;
			nvidia,emc-mrw2 = <0x8020000>;
			nvidia,emc-mrw3 = <0x80d0000>;
			nvidia,emc-mrw4 = <0xc0000000>;
			nvidia,emc-mrw9-0 = <0xc0e6060>;
			nvidia,emc-mrw9-2 = <0xc0e6060>;
			nvidia,emc-mrs = <0x0>;
			nvidia,emc-emrs = <0x0>;
			nvidia,emc-emrs2 = <0x0>;
			nvidia,emc-auto-cal-config = <0xa01a51d8>;
			nvidia,emc-auto-cal-config2 = <0x5500000>;
			nvidia,emc-auto-cal-config3-0 = <0x880000>;
			nvidia,emc-auto-cal-config3-2 = <0x880000>;
			nvidia,emc-auto-cal-config4-0 = <0x880000>;
			nvidia,emc-auto-cal-config4-2 = <0x880000>;
			nvidia,emc-auto-cal-config5-0 = <0x880000>;
			nvidia,emc-auto-cal-config5-2 = <0x880000>;
			nvidia,emc-auto-cal-config6-0 = <0x880000>;
			nvidia,emc-auto-cal-config6-2 = <0x880000>;
			nvidia,emc-auto-cal-config7-0 = <0x880000>;
			nvidia,emc-auto-cal-config7-2 = <0x880000>;
			nvidia,emc-auto-cal-config8-0 = <0x880000>;
			nvidia,emc-auto-cal-config8-2 = <0x880000>;
			nvidia,emc-cfg-2 = <0x110825>;
			nvidia,emc-sel-dpd-ctrl = <0x40008>;
			nvidia,emc-fdpd-ctrl-cmd-no-ramp = <0x1>;
			nvidia,dll-clk-src = <0x40008002>;
			nvidia,clk-out-enb-x-0-clk-enb-emc-dll = <0x1>;
			nvidia,emc-clock-latency-change = <0xd5c>;
		};

		emc-table@1600000 {
			compatible = "nvidia,tegra18-emc-table";
			nvidia,revision = <0xa>;
			nvidia,dvfs-version = "07_1600000_NoCfgVersion_V1.3.4_V4.9";
			clock-frequency = <0x186a00>;
			nvidia,emc-min-mv = <0x44c>;
			nvidia,gk20a-min-mv = <0x44c>;
			nvidia,source = "pllm_ud";
			nvidia,src-sel-reg = <0x80008000>;
			nvidia,mem-pll-ssc-control = <0x1>;
			nvidia,needs-training = <0x2f0>;
			nvidia,training_pattern = <0x0>;
			nvidia,trained = <0x0>;
			nvidia,periodic_training = <0x1>;
			nvidia,trained_dram_clktree_c0d0u0 = <0x0>;
			nvidia,trained_dram_clktree_c0d0u1 = <0x0>;
			nvidia,trained_dram_clktree_c0d1u0 = <0x0>;
			nvidia,trained_dram_clktree_c0d1u1 = <0x0>;
			nvidia,trained_dram_clktree_c1d0u0 = <0x0>;
			nvidia,trained_dram_clktree_c1d0u1 = <0x0>;
			nvidia,trained_dram_clktree_c1d1u0 = <0x0>;
			nvidia,trained_dram_clktree_c1d1u1 = <0x0>;
			nvidia,trained_dram_clktree_c2d0u0 = <0x0>;
			nvidia,trained_dram_clktree_c2d0u1 = <0x0>;
			nvidia,trained_dram_clktree_c2d1u0 = <0x0>;
			nvidia,trained_dram_clktree_c2d1u1 = <0x0>;
			nvidia,trained_dram_clktree_c3d0u0 = <0x0>;
			nvidia,trained_dram_clktree_c3d0u1 = <0x0>;
			nvidia,trained_dram_clktree_c3d1u0 = <0x0>;
			nvidia,trained_dram_clktree_c3d1u1 = <0x0>;
			nvidia,current_dram_clktree_c0d0u0 = <0x0>;
			nvidia,current_dram_clktree_c0d0u1 = <0x0>;
			nvidia,current_dram_clktree_c0d1u0 = <0x0>;
			nvidia,current_dram_clktree_c0d1u1 = <0x0>;
			nvidia,current_dram_clktree_c1d0u0 = <0x0>;
			nvidia,current_dram_clktree_c1d0u1 = <0x0>;
			nvidia,current_dram_clktree_c1d1u0 = <0x0>;
			nvidia,current_dram_clktree_c1d1u1 = <0x0>;
			nvidia,current_dram_clktree_c2d0u0 = <0x0>;
			nvidia,current_dram_clktree_c2d0u1 = <0x0>;
			nvidia,current_dram_clktree_c2d1u0 = <0x0>;
			nvidia,current_dram_clktree_c2d1u1 = <0x0>;
			nvidia,current_dram_clktree_c3d0u0 = <0x0>;
			nvidia,current_dram_clktree_c3d0u1 = <0x0>;
			nvidia,current_dram_clktree_c3d1u0 = <0x0>;
			nvidia,current_dram_clktree_c3d1u1 = <0x0>;
			nvidia,emc_channel_enable = <0xf>;
			nvidia,run_clocks = <0x40>;
			nvidia,tree_margin = <0x1>;
			nvidia,burst-regs-num = <0x92>;
			nvidia,burst-regs-per-ch-num = <0x38>;
			nvidia,burst-pmacro-regs-per-ch-num = <0xa2>;
			nvidia,trim-regs-per-ch-num = <0x14>;
			nvidia,trim-pmacro-regs-per-ch-num = <0x100>;
			nvidia,vref-regs-num = <0x8>;
			nvidia,dram-timing-regs-num = <0x5>;
			nvidia,training-mod-regs-num = <0x28>;
			nvidia,burst-mc-regs-num = <0x25>;
			nvidia,la-scale-regs-num = <0x28>;
			nvidia,emc-ptfv-list = <0x0 0x0 0x0 0x0 0x0 0x0 0x0 0x0 0x0 0x0 0x0 0x0 0x0 0x0 0x0 0x0 0xa 0xa 0xa 0x1>;
			nvidia,emc-registers = <0x60 0x120 0x90 0x0 0x0 0x44 0x1d 0x2a 0x21 0xc 0x2d 0x0 0x4 0x3a 0x23 0x3e 0x41 0x0 0x20 0x1d 0x1d 0x10 0x17 0x16 0x6 0xe 0xc 0xa 0xe 0x8 0xd 0x24 0x9 0x1000001c 0x10000002 0x14 0x803f1f1 0x1d 0x1 0x80000000 0x6000c 0x34 0x3a 0x3c 0x38 0x3a 0x1820 0x0 0x608 0x10 0x10 0x3 0x17 0x3 0x38 0xe 0x2 0x2e 0x12c 0x12c 0xd 0x18 0xc 0x40 0x22 0x4 0x14 0x4803f1f1 0x1860 0x0 0x9980a00d 0x3bff 0x0 0xc00001bb 0x8000 0x64 0x80b6666 0x0 0x0 0x0 0x0 0x409 0x8020221f 0x220f40f 0x12 0x64000 0x310640 0x640002f 0x1900017 0xc1e00309 0x1f13612f 0x200014 0x101fdd 0x331010 0x80d 0x550 0xf3200000 0x8000308c 0x308c 0x2c 0x20000 0x33 0x0 0x11 0x3000 0x2000000 0x2000101 0x0 0xd0909 0x156210 0x140404 0x1fff 0x0 0x80 0x0 0x30 0x40 0x20 0xefff2010 0x0 0x0 0xdcdcdcdc 0xa0a0a0a 0xa0a0a0a 0xa0a0a0a 0x1186190 0x0 0x0 0x3a 0x2c 0x3c 0x8161414 0x34 0x6000c 0x9080 0x7070404 0x40320 0x513801f 0x1f101100 0x14 0x1110fc00 0xf085300 0x1114fc00 0x7004300 0x55553c5a 0x48161414>;
			nvidia,emc-burst-regs-per-ch = <0xfff0000 0xfff0000 0xfff0000 0xfff0000 0xfff0000 0xfff0000 0xfff0000 0xfff0000 0x0 0x0 0x0 0x0 0x880c4848 0x880c4848 0x880c4848 0x880c4848 0x480c4848 0x480c4848 0x480c4848 0x480c4848 0x8c0e4848 0x8c0e4848 0x8c0e4848 0x8c0e4848 0x4c0e4848 0x4c0e4848 0x4c0e4848 0x4c0e4848 0x0 0x0 0x0 0x0 0x0 0x0 0x0 0x0 0x1b 0x1b 0x1b 0x1b 0x1b 0x1b 0x1b 0x1b 0x103200 0x103200 0x103200 0x103200 0x102c00 0x102c00 0x102c00 0x102c00 0x102900 0x102900 0x102900 0x102900>;
			nvidia,emc-pmacro-regs-per-ch = <0xb000b 0xb000b 0xb000b 0xa000a 0x90009 0xa000a 0xc000c 0x90009 0xb 0xb 0x0 0x0 0x0 0x0 0x0 0x0 0x0 0x0 0x0 0x0 0x0 0x0 0x0 0x0 0x0 0x0 0x0 0x0 0x0 0x0 0x0 0x0 0x0 0x0 0x0 0x0 0x0 0x0 0x0 0x0 0x0 0x0 0x0 0x0 0x0 0x0 0x0 0x0 0x0 0x0 0x0 0x0 0x0 0x0 0x0 0x0 0x0 0x0 0x0 0x0 0x0 0x0 0x0 0x0 0x0 0x0 0x0 0x0 0x0 0x0 0x0 0x0 0x0 0x0 0x0 0x0 0x0 0x0 0x0 0x0 0x0 0x0 0x0 0x0 0x0 0x0 0x0 0x0 0x0 0x0 0x0 0x0 0x0 0x0 0x0 0x0 0x0 0x0 0x0 0x0 0x0 0x0 0x0 0x0 0x0 0x0 0x5 0x5 0x7 0x2000a 0x5 0x8 0x2 0x5 0x30005 0x3 0x80005 0x30000 0x5 0x5 0x7 0x2000a 0x5 0x8 0x2 0x5 0x30005 0x3 0x80005 0x30000 0x0 0x0 0x0 0x0 0x0 0x0 0x0 0x0 0x0 0x0 0x0 0x8000000 0x8000000 0x8000000 0x0 0x0 0x8000800 0x800 0x0 0x0 0x0 0x0 0x0 0x0 0x0 0x0 0x0 0x0 0x0 0x0 0x0 0x0>;
			nvidia,emc-shadow-regs-ca-train = <0x60 0x120 0x90 0x0 0x0 0x44 0x1d 0x2a 0x21 0xc 0x2d 0x0 0x4 0x3a 0x23 0x3e 0x41 0x0 0x20 0x1d 0x1d 0x10 0x17 0x16 0x6 0xe 0xc 0xa 0xe 0x8 0xd 0x24 0x9 0x1000001c 0x10000002 0x14 0x803f1f1 0x1d 0x1 0x80000000 0x6000c 0x34 0x3a 0x3c 0x38 0x3a 0x1820 0x0 0x608 0x10 0x10 0x3 0x17 0x3 0x38 0xe 0x2 0x2e 0x12c 0x12c 0xd 0x18 0xc 0x40 0x22 0x4 0x14 0x4803f1f1 0x1860 0x0 0x9980a00d 0x3bff 0x0 0xc00001bb 0x8000 0x64 0x80b6666 0x0 0x0 0x0 0x0 0x409 0x8020221f 0x220f40f 0x12 0x64000 0x310640 0x640002f 0x1900017 0xc1e00309 0x1f13612f 0x200014 0x101fdd 0x331010 0x80d 0x550 0xf3200000 0x8000308c 0x308c 0x2c 0x20000 0x8033 0x0 0x0 0x3000 0x2000000 0x2000101 0x0 0xd0909 0x156210 0x140404 0x1fff 0x0 0x80 0x0 0x30 0x40 0x20 0xefff2010 0x0 0x0 0xdcdcdcdc 0xa0a0a0a 0xa0a0a0a 0xa0a0a0a 0x1186190 0x1 0x1f 0x40 0x2c 0x42 0x8161414 0x34 0x6000c 0x19080 0x7070404 0x40320 0x513801f 0x1f101100 0x14 0x1110fc00 0xf085300 0x1114fc00 0x7004300 0x55553c5a 0x48161414>;
			nvidia,emc-shadow-regs-rdwr-train = <0x60 0x120 0x90 0x0 0x0 0x44 0x1d 0x2a 0x22 0xc 0x2d 0x0 0x4 0x3a 0x23 0x3e 0x41 0x0 0x20 0x1d 0x1d 0x10 0x17 0x16 0x6 0xe 0xc 0xa 0xe 0x8 0xd 0x24 0x9 0x1000001c 0x10000002 0x14 0x803f1f1 0x1d 0x1 0x80000000 0x6000c 0x34 0x3a 0x3c 0x38 0x3a 0x1820 0x0 0x608 0x10 0x10 0x3 0x17 0x3 0x38 0xe 0x2 0x2e 0x12c 0x12c 0xd 0x18 0xc 0x40 0x22 0x4 0x14 0x4803f1f1 0x1860 0x0 0x9980a00d 0x3bff 0x0 0xc00001bb 0x8000 0x64 0x80b6666 0x0 0x0 0x0 0x0 0x409 0x8020221f 0x220f40f 0x12 0x64000 0x310640 0x640002f 0x1900017 0xc1e00309 0x1f13612f 0x200014 0x101fdd 0x331010 0x80d 0x550 0xf3200000 0x8000308c 0x308c 0x2c 0x20000 0x33 0x0 0x11 0x3000 0x2000000 0x2000101 0x0 0xd0909 0x156210 0x140404 0x1fff 0x0 0x80 0x0 0x30 0x40 0x20 0xefff2010 0x0 0x0 0xdcdcdcdc 0xa0a0a0a 0xa0a0a0a 0xa0a0a0a 0x1186190 0x1 0x0 0x3a 0x2c 0x3c 0x8161414 0x34 0x6000c 0xb080 0x7070404 0x40320 0x513801f 0x1f101100 0x14 0x1110fc00 0xf085300 0x1114fc00 0x7004300 0x55553c5a 0x48161414>;
			nvidia,emc-trim-regs-per-ch = <0x0 0x0 0x0 0x0 0x0 0x0 0x0 0x0 0x0 0x0 0x0 0x0 0x0 0x0 0x0 0x0 0x0 0x0 0x0 0x0>;
			nvidia,emc-trim-pmacro-regs-per-ch = <0x11111111 0x11111111 0x11111111 0x11111111 0x11111111 0x11111111 0x11111111 0x11111111 0x220024 0x230026 0x210027 0x240029 0x230029 0x210028 0x230027 0x220027 0xb000b 0xa000b 0xc0009 0x9000a 0x220024 0x230026 0x210027 0x240029 0x230029 0x210028 0x230027 0x220027 0xb000b 0xa000b 0xc0009 0x9000a 0x200020 0x200020 0x200020 0x200020 0x200020 0x200020 0x200020 0x200020 0x200020 0x200020 0x200020 0x200020 0x200020 0x200020 0x200020 0x200020 0x0 0x0 0x0 0x0 0x0 0x0 0x0 0x0 0x0 0x0 0x0 0x0 0x0 0x0 0x0 0x0 0x0 0x0 0x0 0x0 0x0 0x0 0x0 0x0 0x0 0x0 0x0 0x0 0x0 0x0 0x0 0x0 0x0 0x0 0x0 0x0 0x0 0x0 0x0 0x0 0x0 0x0 0x0 0x0 0x0 0x0 0x0 0x0 0x0 0x0 0x0 0x0 0x0 0x0 0x0 0x0 0x0 0x0 0x0 0x0 0x0 0x0 0x0 0x0 0x0 0x0 0x0 0x0 0x0 0x0 0x0 0x0 0x0 0x0 0x0 0x0 0x0 0x0 0x0 0x0 0x0 0x0 0x0 0x0 0x0 0x0 0x0 0x0 0x0 0x0 0x0 0x0 0x0 0x0 0x0 0x0 0x0 0x0 0x0 0x0 0x0 0x0 0x0 0x0 0x0 0x0 0x0 0x0 0x0 0x0 0x0 0x0 0x0 0x0 0x0 0x0 0x0 0x0 0x0 0x0 0x0 0x0 0x0 0x0 0x0 0x0 0x0 0x0 0x0 0x0 0x0 0x0 0x0 0x0 0x0 0x0 0x0 0x0 0x0 0x0 0x0 0x0 0x0 0x0 0x0 0x0 0x0 0x0 0x0 0x0 0x0 0x0 0x0 0x0 0x0 0x0 0x0 0x0 0x0 0x0 0x0 0x0 0x0 0x0 0x0 0x0 0x0 0x0 0x0 0x0 0x0 0x0 0x0 0x0 0x0 0x0 0x0 0x0 0x0 0x0 0x0 0x0 0x0 0x0 0x0 0x0 0x0 0x0 0x0 0x0 0x0 0x0 0x0 0x0 0x0 0x0 0x0 0x0 0x0 0x0 0x0 0x0 0x0 0x0 0x0 0x0 0x0 0x0>;
			nvidia,emc-vref-regs = <0x0 0x0 0x0 0x0 0x0 0x0 0x0 0x0>;
			nvidia,emc-dram-timing-regs = <0x12 0x104 0xb4 0x7 0x20>;
			nvidia,emc-zqcal-param-regs = <0x0 0x0 0x0 0x0 0xf4240 0x960>;
			nvidia,emc-opt-regs = <0x0 0x0 0x0 0x1 0x0 0x0 0x1 0x0>;
			nvidia,emc-training-mod-regs = <0x0 0x0 0x0 0x0 0x0 0x0 0x0 0x0 0x0 0x0 0x0 0x0 0x0 0x0 0x0 0x0 0x0 0x0 0x0 0x0 0x0 0x0 0x0 0x0 0x0 0x0 0x0 0x0 0x0 0x0 0x0 0x0 0x0 0x0 0x0 0x0 0x0 0x0 0x0 0x0>;
			nvidia,emc-save-restore-mod-regs = <0x0 0x0 0x0 0x0 0x0 0x0 0x0 0x0 0x0 0x0 0x0 0x0 0x0 0x0 0x0 0x0>;
			nvidia,emc-burst-mc-regs = <0xc 0x80000100 0x800000f0 0xa1020 0x80001028 0x6 0x7 0x18 0xf 0xf 0x3 0x3 0xd 0x7 0x7 0xc 0x8 0xa 0x23 0x5060303 0xd080c 0x718c2419 0x70000f0f 0x0 0x3f0000 0x3f0000 0x20400000 0x40004 0x80001a 0x80001a 0x80001a 0x80001a 0x80001a 0x80001a 0x80001a 0x80001a 0x80001a>;
			nvidia,emc-la-scale-regs = <0xe7 0x1203 0x80007b 0x80007b 0x8000bd 0x8000ff 0x8000ff 0x8000ff 0x8000f1 0x800004 0xbd 0x800020 0x800020 0x800023 0x800023 0x800020 0x80 0x20 0x800080 0x80 0x64e 0x64e 0x800021 0x80000a 0x8000bd 0x80000a 0x8000bc 0x80007c 0x80000a 0x8000bd 0x800020 0x800050 0x800024 0x80001f 0x800039 0x80000a 0x8000bd 0x800020 0x8000bd 0x800020>;
			nvidia,emc-fdr-sequence-regs = <0x14 0x18 0x1f4 0x1 0x1b 0x19 0x0>;
			nvidia,emc-debug-regs = <0x21 0x0 0x0 0x0 0x0 0x0 0x0>;
			nvidia,emc-mempll-spread-spectrum-regs = <0xc0000000 0xf000e809 0x100df000 0xc0000000 0xf000e809 0x100df000 0xc0000000 0xf000e809 0x100df000 0xc0000000 0xf000e809 0x100df000>;
			nvidia,min-mrs-wait = <0x2f>;
			nvidia,bg-ilvl-ctrl = <0x0>;
			nvidia,emc-mrw = <0x8010054>;
			nvidia,emc-mrw2 = <0x802002d>;
			nvidia,emc-mrw3 = <0x80d0000>;
			nvidia,emc-mrw4 = <0xc0000000>;
			nvidia,emc-mrw9-0 = <0xc0e4848>;
			nvidia,emc-mrw9-2 = <0xc0e4848>;
			nvidia,emc-mrs = <0x0>;
			nvidia,emc-emrs = <0x0>;
			nvidia,emc-emrs2 = <0x0>;
			nvidia,emc-auto-cal-config = <0xa01a51d8>;
			nvidia,emc-auto-cal-config2 = <0x5500000>;
			nvidia,emc-auto-cal-config3-0 = <0x880000>;
			nvidia,emc-auto-cal-config3-2 = <0x880000>;
			nvidia,emc-auto-cal-config4-0 = <0x880000>;
			nvidia,emc-auto-cal-config4-2 = <0x880000>;
			nvidia,emc-auto-cal-config5-0 = <0x880000>;
			nvidia,emc-auto-cal-config5-2 = <0x880000>;
			nvidia,emc-auto-cal-config6-0 = <0x880000>;
			nvidia,emc-auto-cal-config6-2 = <0x880000>;
			nvidia,emc-auto-cal-config7-0 = <0x880000>;
			nvidia,emc-auto-cal-config7-2 = <0x880000>;
			nvidia,emc-auto-cal-config8-0 = <0x880000>;
			nvidia,emc-auto-cal-config8-2 = <0x880000>;
			nvidia,emc-cfg-2 = <0x110835>;
			nvidia,emc-sel-dpd-ctrl = <0x40000>;
			nvidia,emc-fdpd-ctrl-cmd-no-ramp = <0x0>;
			nvidia,dll-clk-src = <0x80008000>;
			nvidia,clk-out-enb-x-0-clk-enb-emc-dll = <0x0>;
			nvidia,emc-clock-latency-change = <0x49c>;
		};
	};

	mail {
		edition = <0x1>;
		dbs = <0x20006>;
	};
};
